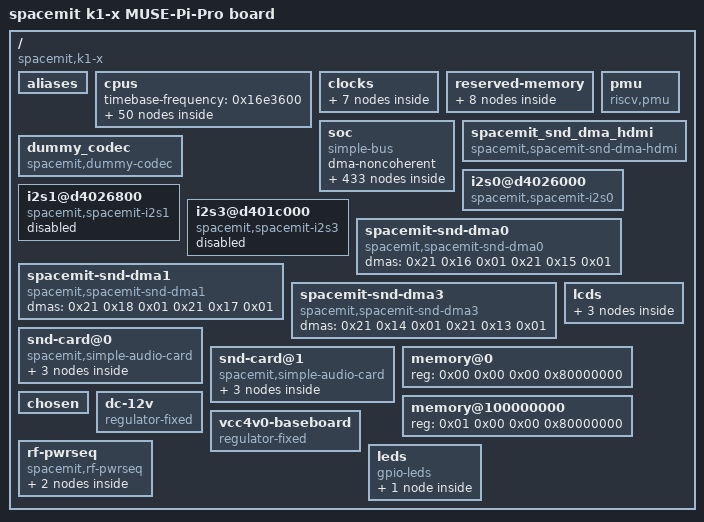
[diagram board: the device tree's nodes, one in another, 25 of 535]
/dts-v1/;

/ {
	compatible = "spacemit,k1-x";
	#address-cells = <0x02>;
	#size-cells = <0x02>;
	model = "spacemit k1-x MUSE-Pi-Pro board";
	modules_usrload = "8852bs";

	aliases {
		serial0 = "/soc/serial@d4017000";
		serial1 = "/soc/uart@f0612000";
		serial2 = "/soc/uart@d4017100";
		serial3 = "/soc/uart@d4017200";
		serial4 = "/soc/uart@d4017300";
		serial5 = "/soc/uart@d4017400";
		serial6 = "/soc/uart@d4017500";
		serial7 = "/soc/uart@d4017600";
		serial8 = "/soc/uart@d4017700";
		serial9 = "/soc/uart@d4017800";
		serial10 = "/soc/r_uart0@c0881000";
		serial11 = "/soc/r_uart1@c088d000";
		mmc0 = "/soc/sdh@d4280000";
		mmc1 = "/soc/sdh@d4280800";
		mmc2 = "/soc/sdh@d4281000";
		ethernet0 = "/soc/ethernet@cac80000";
		ethernet1 = "/soc/ethernet@cac81000";
	};

	cpus {
		#address-cells = <0x01>;
		#size-cells = <0x00>;
		timebase-frequency = <0x16e3600>;

		cpu@0 {
			compatible = "spacemit,x60\0riscv";
			device_type = "cpu";
			model = "Spacemit(R) X60";
			reg = <0x00>;
			status = "okay";
			riscv,isa = "rv64imafdcv";
			riscv,isa-base = "rv64i";
			riscv,isa-extensions = "i\0m\0a\0f\0d\0c\0v\0zicbom\0zicboz\0zicntr\0zicond\0zicsr\0zifencei\0zihintpause\0zihpm\0zfh\0zfhmin\0zba\0zbb\0zbc\0zbs\0zkt\0zvfh\0zvfhmin\0zvkt\0sscofpmf\0sstc\0svinval\0svnapot\0svpbmt";
			riscv,cbom-block-size = <0x40>;
			riscv,cboz-block-size = <0x40>;
			i-cache-block-size = <0x40>;
			i-cache-size = <0x8000>;
			i-cache-sets = <0x80>;
			d-cache-block-size = <0x40>;
			d-cache-size = <0x8000>;
			d-cache-sets = <0x80>;
			next-level-cache = <0x01>;
			mmu-type = "riscv,sv39";
			#cooling-cells = <0x02>;
			clst-supply = <0x02>;
			clocks = <0x03 0x9c 0x03 0xa0>;
			clock-names = "cls0\0cls1";
			operating-points-v2 = <0x04 0x05 0x06>;
			cpu-ai = "true";
			phandle = <0x08>;

			interrupt-controller {
				#interrupt-cells = <0x01>;
				compatible = "riscv,cpu-intc";
				interrupt-controller;
				phandle = <0x10>;
			};
		};

		cpu@1 {
			device_type = "cpu";
			reg = <0x01>;
			status = "okay";
			compatible = "spacemit,x60\0riscv";
			model = "Spacemit(R) X60";
			riscv,isa = "rv64imafdcv";
			riscv,isa-base = "rv64i";
			riscv,isa-extensions = "i\0m\0a\0f\0d\0c\0v\0zicbom\0zicboz\0zicntr\0zicond\0zicsr\0zifencei\0zihintpause\0zihpm\0zfh\0zfhmin\0zba\0zbb\0zbc\0zbs\0zkt\0zvfh\0zvfhmin\0zvkt\0sscofpmf\0sstc\0svinval\0svnapot\0svpbmt";
			riscv,cbom-block-size = <0x40>;
			riscv,cboz-block-size = <0x40>;
			i-cache-block-size = <0x40>;
			i-cache-size = <0x8000>;
			i-cache-sets = <0x80>;
			d-cache-block-size = <0x40>;
			d-cache-size = <0x8000>;
			d-cache-sets = <0x80>;
			next-level-cache = <0x01>;
			mmu-type = "riscv,sv39";
			#cooling-cells = <0x02>;
			clst-supply = <0x02>;
			clocks = <0x03 0x9c 0x03 0xa0>;
			clock-names = "cls0\0cls1";
			operating-points-v2 = <0x04 0x05 0x06>;
			cpu-ai = "true";
			phandle = <0x09>;

			interrupt-controller {
				#interrupt-cells = <0x01>;
				compatible = "riscv,cpu-intc";
				interrupt-controller;
				phandle = <0x11>;
			};
		};

		cpu@2 {
			device_type = "cpu";
			reg = <0x02>;
			status = "okay";
			compatible = "spacemit,x60\0riscv";
			model = "Spacemit(R) X60";
			riscv,isa = "rv64imafdcv";
			riscv,isa-base = "rv64i";
			riscv,isa-extensions = "i\0m\0a\0f\0d\0c\0v\0zicbom\0zicboz\0zicntr\0zicond\0zicsr\0zifencei\0zihintpause\0zihpm\0zfh\0zfhmin\0zba\0zbb\0zbc\0zbs\0zkt\0zvfh\0zvfhmin\0zvkt\0sscofpmf\0sstc\0svinval\0svnapot\0svpbmt";
			riscv,cbom-block-size = <0x40>;
			riscv,cboz-block-size = <0x40>;
			i-cache-block-size = <0x40>;
			i-cache-size = <0x8000>;
			i-cache-sets = <0x80>;
			d-cache-block-size = <0x40>;
			d-cache-size = <0x8000>;
			d-cache-sets = <0x80>;
			next-level-cache = <0x01>;
			mmu-type = "riscv,sv39";
			#cooling-cells = <0x02>;
			clst-supply = <0x02>;
			clocks = <0x03 0x9c 0x03 0xa0>;
			clock-names = "cls0\0cls1";
			operating-points-v2 = <0x04 0x05 0x06>;
			cpu-ai = "true";
			phandle = <0x0a>;

			interrupt-controller {
				#interrupt-cells = <0x01>;
				compatible = "riscv,cpu-intc";
				interrupt-controller;
				phandle = <0x12>;
			};
		};

		cpu@3 {
			device_type = "cpu";
			reg = <0x03>;
			status = "okay";
			compatible = "spacemit,x60\0riscv";
			model = "Spacemit(R) X60";
			riscv,isa = "rv64imafdcv";
			riscv,isa-base = "rv64i";
			riscv,isa-extensions = "i\0m\0a\0f\0d\0c\0v\0zicbom\0zicboz\0zicntr\0zicond\0zicsr\0zifencei\0zihintpause\0zihpm\0zfh\0zfhmin\0zba\0zbb\0zbc\0zbs\0zkt\0zvfh\0zvfhmin\0zvkt\0sscofpmf\0sstc\0svinval\0svnapot\0svpbmt";
			riscv,cbom-block-size = <0x40>;
			riscv,cboz-block-size = <0x40>;
			i-cache-block-size = <0x40>;
			i-cache-size = <0x8000>;
			i-cache-sets = <0x80>;
			d-cache-block-size = <0x40>;
			d-cache-size = <0x8000>;
			d-cache-sets = <0x80>;
			next-level-cache = <0x01>;
			mmu-type = "riscv,sv39";
			#cooling-cells = <0x02>;
			clst-supply = <0x02>;
			clocks = <0x03 0x9c 0x03 0xa0>;
			clock-names = "cls0\0cls1";
			operating-points-v2 = <0x04 0x05 0x06>;
			cpu-ai = "true";
			phandle = <0x0b>;

			interrupt-controller {
				#interrupt-cells = <0x01>;
				compatible = "riscv,cpu-intc";
				interrupt-controller;
				phandle = <0x13>;
			};
		};

		cpu@4 {
			device_type = "cpu";
			reg = <0x04>;
			status = "okay";
			compatible = "spacemit,x60\0riscv";
			model = "Spacemit(R) X60";
			riscv,isa = "rv64imafdcv";
			riscv,isa-base = "rv64i";
			riscv,isa-extensions = "i\0m\0a\0f\0d\0c\0v\0zicbom\0zicboz\0zicntr\0zicond\0zicsr\0zifencei\0zihintpause\0zihpm\0zfh\0zfhmin\0zba\0zbb\0zbc\0zbs\0zkt\0zvfh\0zvfhmin\0zvkt\0sscofpmf\0sstc\0svinval\0svnapot\0svpbmt";
			riscv,cbom-block-size = <0x40>;
			riscv,cboz-block-size = <0x40>;
			i-cache-block-size = <0x40>;
			i-cache-size = <0x8000>;
			i-cache-sets = <0x80>;
			d-cache-block-size = <0x40>;
			d-cache-size = <0x8000>;
			d-cache-sets = <0x80>;
			next-level-cache = <0x07>;
			mmu-type = "riscv,sv39";
			#cooling-cells = <0x02>;
			clst-supply = <0x02>;
			clocks = <0x03 0x9c 0x03 0xa0>;
			clock-names = "cls0\0cls1";
			operating-points-v2 = <0x04 0x05 0x06>;
			phandle = <0x0c>;

			interrupt-controller {
				#interrupt-cells = <0x01>;
				compatible = "riscv,cpu-intc";
				interrupt-controller;
				phandle = <0x14>;
			};
		};

		cpu@5 {
			device_type = "cpu";
			reg = <0x05>;
			status = "okay";
			compatible = "spacemit,x60\0riscv";
			model = "Spacemit(R) X60";
			riscv,isa = "rv64imafdcv";
			riscv,isa-base = "rv64i";
			riscv,isa-extensions = "i\0m\0a\0f\0d\0c\0v\0zicbom\0zicboz\0zicntr\0zicond\0zicsr\0zifencei\0zihintpause\0zihpm\0zfh\0zfhmin\0zba\0zbb\0zbc\0zbs\0zkt\0zvfh\0zvfhmin\0zvkt\0sscofpmf\0sstc\0svinval\0svnapot\0svpbmt";
			riscv,cbom-block-size = <0x40>;
			riscv,cboz-block-size = <0x40>;
			i-cache-block-size = <0x40>;
			i-cache-size = <0x8000>;
			i-cache-sets = <0x80>;
			d-cache-block-size = <0x40>;
			d-cache-size = <0x8000>;
			d-cache-sets = <0x80>;
			next-level-cache = <0x07>;
			mmu-type = "riscv,sv39";
			#cooling-cells = <0x02>;
			clst-supply = <0x02>;
			clocks = <0x03 0x9c 0x03 0xa0>;
			clock-names = "cls0\0cls1";
			operating-points-v2 = <0x04 0x05 0x06>;
			phandle = <0x0d>;

			interrupt-controller {
				#interrupt-cells = <0x01>;
				compatible = "riscv,cpu-intc";
				interrupt-controller;
				phandle = <0x15>;
			};
		};

		cpu@6 {
			device_type = "cpu";
			reg = <0x06>;
			status = "okay";
			compatible = "spacemit,x60\0riscv";
			model = "Spacemit(R) X60";
			riscv,isa = "rv64imafdcv";
			riscv,isa-base = "rv64i";
			riscv,isa-extensions = "i\0m\0a\0f\0d\0c\0v\0zicbom\0zicboz\0zicntr\0zicond\0zicsr\0zifencei\0zihintpause\0zihpm\0zfh\0zfhmin\0zba\0zbb\0zbc\0zbs\0zkt\0zvfh\0zvfhmin\0zvkt\0sscofpmf\0sstc\0svinval\0svnapot\0svpbmt";
			riscv,cbom-block-size = <0x40>;
			riscv,cboz-block-size = <0x40>;
			i-cache-block-size = <0x40>;
			i-cache-size = <0x8000>;
			i-cache-sets = <0x80>;
			d-cache-block-size = <0x40>;
			d-cache-size = <0x8000>;
			d-cache-sets = <0x80>;
			next-level-cache = <0x07>;
			mmu-type = "riscv,sv39";
			#cooling-cells = <0x02>;
			clst-supply = <0x02>;
			clocks = <0x03 0x9c 0x03 0xa0>;
			clock-names = "cls0\0cls1";
			operating-points-v2 = <0x04 0x05 0x06>;
			phandle = <0x0e>;

			interrupt-controller {
				#interrupt-cells = <0x01>;
				compatible = "riscv,cpu-intc";
				interrupt-controller;
				phandle = <0x16>;
			};
		};

		cpu@7 {
			device_type = "cpu";
			reg = <0x07>;
			status = "okay";
			compatible = "spacemit,x60\0riscv";
			model = "Spacemit(R) X60";
			riscv,isa = "rv64imafdcv";
			riscv,isa-base = "rv64i";
			riscv,isa-extensions = "i\0m\0a\0f\0d\0c\0v\0zicbom\0zicboz\0zicntr\0zicond\0zicsr\0zifencei\0zihintpause\0zihpm\0zfh\0zfhmin\0zba\0zbb\0zbc\0zbs\0zkt\0zvfh\0zvfhmin\0zvkt\0sscofpmf\0sstc\0svinval\0svnapot\0svpbmt";
			riscv,cbom-block-size = <0x40>;
			riscv,cboz-block-size = <0x40>;
			i-cache-block-size = <0x40>;
			i-cache-size = <0x8000>;
			i-cache-sets = <0x80>;
			d-cache-block-size = <0x40>;
			d-cache-size = <0x8000>;
			d-cache-sets = <0x80>;
			next-level-cache = <0x07>;
			mmu-type = "riscv,sv39";
			#cooling-cells = <0x02>;
			clst-supply = <0x02>;
			clocks = <0x03 0x9c 0x03 0xa0>;
			clock-names = "cls0\0cls1";
			operating-points-v2 = <0x04 0x05 0x06>;
			phandle = <0x0f>;

			interrupt-controller {
				#interrupt-cells = <0x01>;
				compatible = "riscv,cpu-intc";
				interrupt-controller;
				phandle = <0x17>;
			};
		};

		l2-cache0 {
			compatible = "cache";
			cache-block-size = <0x40>;
			cache-level = <0x02>;
			cache-size = <0x80000>;
			cache-sets = <0x200>;
			cache-unified;
			phandle = <0x01>;
		};

		l2-cache1 {
			compatible = "cache";
			cache-block-size = <0x40>;
			cache-level = <0x02>;
			cache-size = <0x80000>;
			cache-sets = <0x200>;
			cache-unified;
			phandle = <0x07>;
		};

		opp_table0 {
			compatible = "operating-points-v2";
			opp-shared;
			clocks = <0x03 0x9d 0x03 0xa1 0x03 0x9e 0x03 0x99 0x03 0x01 0x03 0x9b 0x03 0x9f>;
			clock-names = "ace0\0ace1\0tcm\0cci\0pll3\0c0hi\0c1hi";
			cci-hz = <0x00 0x2498e580>;
			phandle = <0x04>;

			opp1800000000 {
				opp-hz = <0x00 0x6b49d200 0x00 0x6b49d200>;
				tcm-hz = <0x00 0x35a4e900>;
				ace-hz = <0x00 0x35a4e900>;
				opp-microvolt = <0x11b340>;
				clock-latency-ns = <0x30d40>;
				turbo-mode;
			};

			opp1600000000 {
				opp-hz = <0x00 0x5f5e1000 0x00 0x5f5e1000>;
				tcm-hz = <0x00 0x2faf0800>;
				ace-hz = <0x00 0x2faf0800>;
				opp-microvolt = <0x100590>;
				clock-latency-ns = <0x30d40>;
			};

			opp1228800000 {
				opp-hz = <0x00 0x493e0000 0x00 0x493e0000>;
				tcm-hz = <0x00 0x249f0000>;
				ace-hz = <0x00 0x249f0000>;
				opp-microvolt = <0xe7ef0>;
				clock-latency-ns = <0x30d40>;
			};

			opp1000000000 {
				opp-hz = <0x00 0x3b9aca00 0x00 0x3b9aca00>;
				tcm-hz = <0x00 0x1dcd6500>;
				ace-hz = <0x00 0x1dcd6500>;
				opp-microvolt = <0xe7ef0>;
				clock-latency-ns = <0x30d40>;
			};

			opp819000000 {
				opp-hz = <0x00 0x30d0f2c0 0x00 0x30d0f2c0>;
				opp-microvolt = <0xe7ef0>;
				tcm-hz = <0x00 0x18687960>;
				ace-hz = <0x00 0x18687960>;
				clock-latency-ns = <0x30d40>;
			};

			opp614400000 {
				opp-hz = <0x00 0x249f0000 0x00 0x249f0000>;
				tcm-hz = <0x00 0x124f8000>;
				ace-hz = <0x00 0x124f8000>;
				opp-microvolt = <0xe7ef0>;
				clock-latency-ns = <0x30d40>;
			};
		};

		opp_table1 {
			compatible = "operating-points-v2";
			opp-shared;
			clocks = <0x03 0x9d 0x03 0xa1 0x03 0x9e 0x03 0x99 0x03 0x01 0x03 0x9b 0x03 0x9f>;
			clock-names = "ace0\0ace1\0tcm\0cci\0pll3\0c0hi\0c1hi";
			cci-hz = <0x00 0x2498e580>;
			phandle = <0x05>;

			opp1800000000 {
				opp-hz = <0x00 0x6b49d200 0x00 0x6b49d200>;
				tcm-hz = <0x00 0x35a4e900>;
				ace-hz = <0x00 0x35a4e900>;
				opp-microvolt = <0x10c8e0>;
				clock-latency-ns = <0x30d40>;
				turbo-mode;
			};

			opp1600000000 {
				opp-hz = <0x00 0x5f5e1000 0x00 0x5f5e1000>;
				tcm-hz = <0x00 0x2faf0800>;
				ace-hz = <0x00 0x2faf0800>;
				opp-microvolt = <0x100590>;
				clock-latency-ns = <0x30d40>;
			};

			opp1228800000 {
				opp-hz = <0x00 0x493e0000 0x00 0x493e0000>;
				tcm-hz = <0x00 0x249f0000>;
				ace-hz = <0x00 0x249f0000>;
				opp-microvolt = <0xe7ef0>;
				clock-latency-ns = <0x30d40>;
			};

			opp1000000000 {
				opp-hz = <0x00 0x3b9aca00 0x00 0x3b9aca00>;
				tcm-hz = <0x00 0x1dcd6500>;
				ace-hz = <0x00 0x1dcd6500>;
				opp-microvolt = <0xe7ef0>;
				clock-latency-ns = <0x30d40>;
			};

			opp819000000 {
				opp-hz = <0x00 0x30d0f2c0 0x00 0x30d0f2c0>;
				opp-microvolt = <0xe7ef0>;
				tcm-hz = <0x00 0x18687960>;
				ace-hz = <0x00 0x18687960>;
				clock-latency-ns = <0x30d40>;
			};

			opp614400000 {
				opp-hz = <0x00 0x249f0000 0x00 0x249f0000>;
				tcm-hz = <0x00 0x124f8000>;
				ace-hz = <0x00 0x124f8000>;
				opp-microvolt = <0xe7ef0>;
				clock-latency-ns = <0x30d40>;
			};
		};

		opp_table2 {
			compatible = "operating-points-v2";
			opp-shared;
			clocks = <0x03 0x9d 0x03 0xa1 0x03 0x9e 0x03 0x99 0x03 0x01 0x03 0x9b 0x03 0x9f>;
			clock-names = "ace0\0ace1\0tcm\0cci\0pll3\0c0hi\0c1hi";
			cci-hz = <0x00 0x2498e580>;
			phandle = <0x06>;

			opp1800000000 {
				opp-hz = <0x00 0x6b49d200 0x00 0x6b49d200>;
				tcm-hz = <0x00 0x35a4e900>;
				ace-hz = <0x00 0x35a4e900>;
				opp-microvolt = <0x100590>;
				clock-latency-ns = <0x30d40>;
				turbo-mode;
			};

			opp1600000000 {
				opp-hz = <0x00 0x5f5e1000 0x00 0x5f5e1000>;
				tcm-hz = <0x00 0x2faf0800>;
				ace-hz = <0x00 0x2faf0800>;
				opp-microvolt = <0x100590>;
				clock-latency-ns = <0x30d40>;
			};

			opp1228800000 {
				opp-hz = <0x00 0x493e0000 0x00 0x493e0000>;
				tcm-hz = <0x00 0x249f0000>;
				ace-hz = <0x00 0x249f0000>;
				opp-microvolt = <0xe7ef0>;
				clock-latency-ns = <0x30d40>;
			};

			opp1000000000 {
				opp-hz = <0x00 0x3b9aca00 0x00 0x3b9aca00>;
				tcm-hz = <0x00 0x1dcd6500>;
				ace-hz = <0x00 0x1dcd6500>;
				opp-microvolt = <0xe7ef0>;
				clock-latency-ns = <0x30d40>;
			};

			opp819000000 {
				opp-hz = <0x00 0x30d0f2c0 0x00 0x30d0f2c0>;
				opp-microvolt = <0xe7ef0>;
				tcm-hz = <0x00 0x18687960>;
				ace-hz = <0x00 0x18687960>;
				clock-latency-ns = <0x30d40>;
			};

			opp614400000 {
				opp-hz = <0x00 0x249f0000 0x00 0x249f0000>;
				tcm-hz = <0x00 0x124f8000>;
				ace-hz = <0x00 0x124f8000>;
				opp-microvolt = <0xe7ef0>;
				clock-latency-ns = <0x30d40>;
			};
		};

		cpu-map {

			cluster0 {

				core0 {
					cpu = <0x08>;
				};

				core1 {
					cpu = <0x09>;
				};

				core2 {
					cpu = <0x0a>;
				};

				core3 {
					cpu = <0x0b>;
				};
			};

			cluster1 {

				core0 {
					cpu = <0x0c>;
				};

				core1 {
					cpu = <0x0d>;
				};

				core2 {
					cpu = <0x0e>;
				};

				core3 {
					cpu = <0x0f>;
				};
			};
		};
	};

	clocks {
		#address-cells = <0x02>;
		#size-cells = <0x02>;
		ranges;

		clock-vctcxo_24 {
			#clock-cells = <0x00>;
			compatible = "fixed-clock";
			clock-frequency = <0x16e3600>;
			clock-output-names = "vctcxo_24";
			phandle = <0x18>;
		};

		clock-vctcxo_3 {
			#clock-cells = <0x00>;
			compatible = "fixed-clock";
			clock-frequency = <0x2dc6c0>;
			clock-output-names = "vctcxo_3";
			phandle = <0x19>;
		};

		clock-vctcxo_1 {
			#clock-cells = <0x00>;
			compatible = "fixed-clock";
			clock-frequency = <0xf4240>;
			clock-output-names = "vctcxo_1";
			phandle = <0x1a>;
		};

		clock-pll1_2457p6_vco {
			#clock-cells = <0x00>;
			compatible = "fixed-clock";
			clock-frequency = <0x927c0000>;
			clock-output-names = "pll1_2457p6_vco";
			phandle = <0x1b>;
		};

		clock-clk32k {
			#clock-cells = <0x00>;
			compatible = "fixed-clock";
			clock-frequency = <0x7d00>;
			clock-output-names = "clk_32k";
			phandle = <0x1c>;
		};

		clock-pll_clk_cluster0 {
			#clock-cells = <0x00>;
			compatible = "fixed-clock";
			clock-frequency = <0x989680>;
			clock-output-names = "pll_clk_cluster0";
		};

		clock-pll_clk_cluster1 {
			#clock-cells = <0x00>;
			compatible = "fixed-clock";
			clock-frequency = <0x989680>;
			clock-output-names = "pll_clk_cluster1";
		};
	};

	reserved-memory {
		#address-cells = <0x02>;
		#size-cells = <0x02>;
		ranges;

		rcpu_mem_heap@100000 {
			reg = <0x00 0x100000 0x00 0x200000>;
			da_base = <0x30000000>;
			no-map;
			phandle = <0x28>;
		};

		vdev0vring0@300000 {
			reg = <0x00 0x300000 0x00 0x3000>;
			da_base = "0 \0";
			no-map;
			phandle = <0x29>;
		};

		vdev0vring1@303000 {
			reg = <0x00 0x303000 0x00 0x3000>;
			da_base = "0 0";
			no-map;
			phandle = <0x2a>;
		};

		vdev0buffer@306000 {
			compatible = "shared-dma-pool";
			reg = <0x00 0x306000 0x00 0xf6000>;
			da_base = "0 `";
			no-map;
			phandle = <0x2b>;
		};

		rsc_table@3fc000 {
			reg = <0x00 0x3fc000 0x00 0x4000>;
			da_base = <0x302fc000>;
			no-map;
			phandle = <0x2c>;
		};

		rcpu_mem_0@400000 {
			reg = <0x00 0x400000 0x00 0x200000>;
			da_base = "00\0";
			no-map;
			phandle = <0x27>;
		};

		linux,cma {
			compatible = "shared-dma-pool";
			alloc-ranges = <0x00 0x40000000 0x00 0x30000000>;
			size = <0x00 0x18000000>;
			alignment = <0x00 0x100000>;
			linux,cma-default;
			reusable;
		};

		dpu_reserved@2ff40000 {
			compatible = "shared-dma-pool";
			reg = <0x00 0x2ff40000 0x00 0xc0000>;
			no-map;
			phandle = <0x6a>;
		};
	};

	soc {
		compatible = "simple-bus";
		#address-cells = <0x02>;
		#size-cells = <0x02>;
		dma-noncoherent;
		ranges;

		dram_range@0 {
			compatible = "spacemit-dram-bus";
			#address-cells = <0x02>;
			#size-cells = <0x02>;
			dma-ranges = <0x00 0x00 0x00 0x00 0x00 0x80000000>;
			#interconnect-cells = <0x00>;
			status = "okay";
			phandle = <0x47>;
		};

		dram_range@1 {
			compatible = "spacemit-dram-bus";
			#address-cells = <0x02>;
			#size-cells = <0x02>;
			dma-ranges = <0x00 0x00 0x00 0x00 0x00 0x80000000 0x00 0x80000000 0x01 0x00 0x03 0x80000000>;
			#interconnect-cells = <0x00>;
			status = "okay";
			phandle = <0x61>;
		};

		dram_range@2 {
			compatible = "spacemit-dram-bus";
			#address-cells = <0x02>;
			#size-cells = <0x02>;
			dma-ranges = <0x00 0x00 0x00 0x00 0x00 0x80000000 0x00 0x90000000 0x01 0x10000000 0x03 0x70000000>;
			#interconnect-cells = <0x00>;
			status = "okay";
			phandle = <0x53>;
		};

		dram_range@3 {
			compatible = "spacemit-dram-bus";
			#address-cells = <0x02>;
			#size-cells = <0x02>;
			dma-ranges = <0x00 0x00 0x00 0x00 0x00 0x80000000 0x00 0x80000000 0x01 0x00 0x01 0x80000000>;
			#interconnect-cells = <0x00>;
			status = "okay";
			phandle = <0x62>;
		};

		dram_range@4 {
			compatible = "spacemit-dram-bus";
			#address-cells = <0x02>;
			#size-cells = <0x02>;
			dma-ranges = <0x00 0x00 0x00 0x00 0x00 0x80000000 0x01 0x00 0x01 0x80000000 0x03 0x00>;
			#interconnect-cells = <0x00>;
			status = "okay";
			phandle = <0x22>;
		};

		dram_range@5 {
			compatible = "spacemit-dram-bus";
			#address-cells = <0x02>;
			#size-cells = <0x02>;
			dma-ranges = <0x00 0x00 0x00 0x00 0x00 0x80000000 0x00 0x80000000 0x01 0x00 0x00 0x80000000>;
			#interconnect-cells = <0x00>;
			status = "okay";
			phandle = <0x42>;
		};

		dram_range@6 {
			compatible = "spacemit-dram-bus";
			#address-cells = <0x02>;
			#size-cells = <0x02>;
			dma-ranges = <0x00 0x00 0x00 0x00 0x00 0x80000000 0x00 0x80000000 0x01 0x00 0x00 0x10000000 0x00 0xa0000000 0x01 0x20000000 0x03 0x60000000>;
			#interconnect-cells = <0x00>;
			status = "okay";
			phandle = <0x55>;
		};

		dram_range@7 {
			compatible = "spacemit-dram-bus";
			#address-cells = <0x02>;
			#size-cells = <0x02>;
			dma-ranges = <0x00 0x00 0x00 0x00 0x00 0x80000000 0x00 0x80000000 0x01 0x00 0x00 0x20000000 0x00 0xb8000000 0x01 0x38000000 0x03 0x48000000>;
			#interconnect-cells = <0x00>;
			status = "okay";
			phandle = <0x58>;
		};

		dram_range@8 {
			compatible = "spacemit-dram-bus";
			#address-cells = <0x02>;
			#size-cells = <0x02>;
			dma-ranges = <0x00 0x30200000 0x00 0x300000 0x00 0xfc000>;
			#interconnect-cells = <0x00>;
			status = "okay";
			phandle = <0x26>;
		};

		clint@e4000000 {
			compatible = "riscv,clint0";
			interrupts-extended = <0x10 0x03 0x10 0x07 0x11 0x03 0x11 0x07 0x12 0x03 0x12 0x07 0x13 0x03 0x13 0x07 0x14 0x03 0x14 0x07 0x15 0x03 0x15 0x07 0x16 0x03 0x16 0x07 0x17 0x03 0x17 0x07>;
			reg = <0x00 0xe4000000 0x00 0x10000>;
		};

		clock-controller@d4050000 {
			compatible = "spacemit,k1x-clock";
			reg = <0x00 0xd4050000 0x00 0x209c 0x00 0xd4282800 0x00 0x400 0x00 0xd4015000 0x00 0x1000 0x00 0xd4090000 0x00 0x1000 0x00 0xd4282c00 0x00 0x400 0x00 0xd8440000 0x00 0x98 0x00 0xc0000000 0x00 0x4280 0x00 0xf0610000 0x00 0x20 0x00 0xc0880000 0x00 0x2050 0x00 0xc0888000 0x00 0x30 0x00 0xc088c000 0x00 0x40>;
			reg-names = "mpmu\0apmu\0apbc\0apbs\0ciu\0dciu\0ddrc\0apbc2\0rcpu\0rcpu2\0audpmu";
			clocks = <0x18 0x19 0x1a 0x1b 0x1c>;
			clock-names = "vctcxo_24\0vctcxo_3\0vctcxo_1\0pll1_2457p6_vco\0clk_32k";
			#clock-cells = <0x01>;
			status = "okay";
			phandle = <0x03>;
		};

		reset-controller@d4050000 {
			compatible = "spacemit,k1x-reset";
			reg = <0x00 0xd4050000 0x00 0x209c 0x00 0xd4282800 0x00 0x400 0x00 0xd4015000 0x00 0x1000 0x00 0xd4090000 0x00 0x1000 0x00 0xd4282c00 0x00 0x400 0x00 0xd8440000 0x00 0x98 0x00 0xc0000000 0x00 0x4280 0x00 0xf0610000 0x00 0x20 0x00 0xc0880000 0x00 0x2050 0x00 0xc0888000 0x00 0x30>;
			reg-names = "mpmu\0apmu\0apbc\0apbs\0ciu\0dciu\0ddrc\0apbc2\0rcpu\0rcpu2";
			#reset-cells = <0x01>;
			status = "okay";
			phandle = <0x1d>;
		};

		interrupt-controller@e0000000 {
			#interrupt-cells = <0x01>;
			compatible = "riscv,plic0";
			interrupt-controller;
			interrupts-extended = <0x10 0x0b 0x10 0x09 0x11 0x0b 0x11 0x09 0x12 0x0b 0x12 0x09 0x13 0x0b 0x13 0x09 0x14 0x0b 0x14 0x09 0x15 0x0b 0x15 0x09 0x16 0x0b 0x16 0x09 0x17 0x0b 0x17 0x09>;
			reg = <0x00 0xe0000000 0x00 0x4000000>;
			reg-names = "control";
			riscv,max-priority = <0x07>;
			riscv,ndev = <0x9f>;
			phandle = <0x1e>;
		};

		pinctrl@d401e000 {
			compatible = "pinconf-single-aib";
			reg = <0x00 0xd401e000 0x00 0x27c 0x00 0xd4019800 0x00 0x10 0x00 0xd4019000 0x00 0x800 0x00 0xd4282904 0x00 0x04>;
			#address-cells = <0x01>;
			#size-cells = <0x01>;
			#pinctrl-cells = <0x02>;
			#gpio-range-cells = <0x03>;
			pinctrl-single,register-width = <0x20>;
			pinctrl-single,function-mask = <0xff77>;
			clocks = <0x03 0x64>;
			clock-names = "clk_aib";
			resets = <0x1d 0x1d>;
			reset-names = "aib_rst";
			interrupt-parent = <0x1e>;
			interrupts = <0x3c>;
			interrupt-controller;
			#interrupt-cells = <0x01>;
			pinctrl-single,gpio-range = <0x1f 0x32 0x02 0xc440 0x1f 0x3b 0x01 0xd040 0x1f 0x40 0x01 0xd040 0x1f 0x41 0x01 0xd041 0x1f 0x42 0x01 0xd040 0x1f 0x44 0x01 0xc440 0x1f 0x47 0x02 0xd041 0x1f 0x49 0x01 0xb041 0x1f 0x4a 0x01 0xd041 0x1f 0x4b 0x01 0xd040 0x1f 0x50 0x01 0xd040 0x1f 0x51 0x01 0xc440 0x1f 0x52 0x03 0xd040 0x1f 0x7f 0x01 0xb040 0x1f 0x80 0x02 0xd040 0x1f 0x78 0x01 0xb041 0x1f 0x79 0x01 0xa041 0x1f 0x74 0x01 0xb040 0x1f 0x83 0x01 0xb040 0x1f 0x85 0x01 0xb040 0x1f 0x86 0x01 0xb040 0x1f 0x87 0x01 0xb040 0x1f 0x88 0x01 0xd040 0x1f 0x8a 0x01 0xd040 0x1f 0x8f 0x01 0xa040 0x1f 0x90 0x01 0xd040 0x1f 0x91 0x03 0xb040>;
			phandle = <0x3f>;

			gpio-range {
				#pinctrl-single,gpio-range-cells = <0x03>;
				phandle = <0x1f>;
			};

			uart0_0_grp {
				pinctrl-single,pins = <0x1b8 0x03 0xc440 0x1bc 0x03 0xc440>;
			};

			uart0_1_grp {
				pinctrl-single,pins = <0x1c8 0x01 0xc440 0x144 0x03 0xc440>;
			};

			uart0_2_grp {
				pinctrl-single,pins = <0x114 0x02 0xd040 0x118 0x02 0xd040>;
				phandle = <0x23>;
			};

			uart2_grp {
				pinctrl-single,pins = <0x58 0x01 0xd040 0x5c 0x01 0xd040 0x60 0x01 0xd040 0x64 0x01 0xd040>;
				phandle = <0x24>;
			};

			uart3_0_grp {
				pinctrl-single,pins = <0x148 0x02 0xd040 0x14c 0x02 0xd040 0x150 0x02 0xd040 0x154 0x02 0xd040>;
			};

			uart3_1_grp {
				pinctrl-single,pins = <0x4c 0x02 0xd040 0x50 0x02 0xd040 0x54 0x02 0xd040 0x58 0x02 0xd040>;
			};

			uart3_2_grp {
				pinctrl-single,pins = <0xd8 0x04 0xd040 0xdc 0x04 0xd040 0xe0 0x04 0xd040 0xe4 0x04 0xd040>;
			};

			uart4_0_grp {
				pinctrl-single,pins = <0x16c 0x04 0xc440 0x168 0x04 0xc440>;
			};

			uart4_1_grp {
				pinctrl-single,pins = <0x148 0x03 0xd040 0x14c 0x03 0xd040 0x150 0x03 0xd040 0x154 0x03 0xd040>;
			};

			uart4_2_grp {
				pinctrl-single,pins = <0x60 0x02 0xd040 0x64 0x02 0xd040>;
			};

			uart4_3_grp {
				pinctrl-single,pins = <0x88 0x02 0xd040 0x8c 0x02 0xd040 0x90 0x02 0xd040 0x94 0x02 0xd040>;
				phandle = <0x92>;
			};

			uart4_4_grp {
				pinctrl-single,pins = <0x20c 0x04 0xd040 0x210 0x04 0xd040 0x214 0x04 0xd040 0x218 0x04 0xd040>;
			};

			uart5_0_grp {
				pinctrl-single,pins = <0x17c 0x03 0xc440 0x178 0x03 0xc440>;
			};

			uart5_1_grp {
				pinctrl-single,pins = <0x68 0x02 0xd040 0x6c 0x02 0xd040 0x70 0x02 0xd040 0x74 0x02 0xd040>;
			};

			uart5_2_grp {
				pinctrl-single,pins = <0xac 0x02 0xd040 0xb0 0x02 0xd040 0xb4 0x02 0xd040 0xb8 0x02 0xd040>;
			};

			uart5_3_grp {
				pinctrl-single,pins = <0x11c 0x04 0xd040 0x120 0x04 0xd040 0x124 0x04 0xd040 0x128 0x04 0xd040>;
				phandle = <0x91>;
			};

			uart6_0_grp {
				pinctrl-single,pins = <0x158 0x02 0xd040 0x1ec 0x02 0xd040 0x1f0 0x02 0xd040 0x1fc 0x02 0xd040>;
			};

			uart6_1_grp {
				pinctrl-single,pins = <0x04 0x02 0xd040 0x08 0x02 0xd040 0x0c 0x02 0xd040 0x10 0x02 0xd040>;
			};

			uart6_2_grp {
				pinctrl-single,pins = <0xe4 0x02 0xd040 0xe8 0x02 0xd040>;
			};

			uart7_0_grp {
				pinctrl-single,pins = <0x1f4 0x02 0xd040 0x1f8 0x02 0xd040>;
			};

			uart7_1_grp {
				pinctrl-single,pins = <0x14 0x02 0xd040 0x18 0x02 0xd040 0x1c 0x02 0xd040 0x20 0x02 0xd040>;
			};

			uart8_0_grp {
				pinctrl-single,pins = <0x14c 0x04 0xd040 0x150 0x04 0xd040>;
			};

			uart8_1_grp {
				pinctrl-single,pins = <0x24 0x02 0xd040 0x28 0x02 0xd040 0x2c 0x02 0xd040 0x30 0x02 0xd040>;
			};

			uart8_2_grp {
				pinctrl-single,pins = <0x130 0x04 0xc440 0x134 0x04 0xc440 0x138 0x04 0xc440 0x13c 0x04 0xc440>;
			};

			uart9_0_grp {
				pinctrl-single,pins = <0x34 0x02 0xd040 0x38 0x02 0xd040>;
			};

			uart9_1_grp {
				pinctrl-single,pins = <0x1d0 0x03 0xd040 0x21c 0x03 0xd040 0x220 0x03 0xd040 0x224 0x03 0xd040>;
			};

			uart9_2_grp {
				pinctrl-single,pins = <0x124 0x02 0xd040 0x128 0x02 0xd040>;
			};

			i2c0_grp {
				pinctrl-single,pins = <0xdc 0x01 0xd040 0xe0 0x01 0xd040>;
				phandle = <0x2f>;
			};

			r_uart1_grp {
				pinctrl-single,pins = <0xc8 0x02 0xc440 0xcc 0x02 0xc440 0xd0 0x02 0xc440 0xd4 0x02 0xc440>;
			};

			i2c1_grp {
				pinctrl-single,pins = <0xe4 0x01 0xd040 0xe8 0x01 0xd040>;
				phandle = <0x30>;
			};

			i2c2_0_grp {
				pinctrl-single,pins = <0x154 0x04 0xd040 0x158 0x04 0xd040>;
				phandle = <0x31>;
			};

			i2c2_1_grp {
				pinctrl-single,pins = <0x11c 0x02 0xd040 0x120 0x02 0xd040>;
			};

			i2c2_2_grp {
				pinctrl-single,pins = <0x114 0x03 0xd040 0x118 0x03 0xd040>;
			};

			i2c3_0_grp {
				pinctrl-single,pins = <0x9c 0x02 0xd040 0xa0 0x02 0xd040>;
				phandle = <0x33>;
			};

			i2c3_1_grp {
				pinctrl-single,pins = <0xc0 0x04 0xd040 0xc4 0x04 0xd040>;
			};

			i2c3_2_grp {
				pinctrl-single,pins = <0x138 0x03 0xd040 0x13c 0x03 0xd040>;
			};

			i2c4_0_grp {
				pinctrl-single,pins = <0xa4 0x02 0xd040 0xa8 0x02 0xd040>;
				phandle = <0x34>;
			};

			i2c4_1_grp {
				pinctrl-single,pins = <0x130 0x05 0xd040 0x134 0x05 0xd040>;
			};

			i2c4_2_grp {
				pinctrl-single,pins = <0xd0 0x04 0xd040 0xd4 0x04 0xd040>;
			};

			i2c5_0_grp {
				pinctrl-single,pins = <0x148 0x05 0xd040 0x14c 0x05 0xd040>;
				phandle = <0x35>;
			};

			i2c5_1_grp {
				pinctrl-single,pins = <0xdc 0x05 0xd040 0xe0 0x05 0xd040>;
			};

			i2c6_0_grp {
				pinctrl-single,pins = <0x150 0x05 0xd040 0x1fc 0x05 0xd040>;
			};

			i2c6_1_grp {
				pinctrl-single,pins = <0x228 0x02 0xd040 0x22c 0x02 0xd040>;
			};

			i2c6_2_grp {
				pinctrl-single,pins = <0xe4 0x05 0xd040 0xe8 0x05 0xd040>;
				phandle = <0x37>;
			};

			i2c7_grp {
				pinctrl-single,pins = <0x228 0x01 0xd040 0x22c 0x01 0xd040>;
				phandle = <0x38>;
			};

			i2c8_grp {
				pinctrl-single,pins = <0x1d4 0x00 0xd040 0x1d8 0x00 0xd040>;
				phandle = <0x39>;
			};

			one_wire_0_grp {
				pinctrl-single,pins = <0x1d0 0x05 0xd040>;
			};

			one_wire_1_grp {
				pinctrl-single,pins = <0xc0 0x05 0xc440>;
			};

			ir_rx_0_grp {
				pinctrl-single,pins = <0x1e4 0x02 0xd040>;
			};

			ir_rx_1_grp {
				pinctrl-single,pins = <0x140 0x01 0xc440>;
			};

			ir_rx_2_grp {
				pinctrl-single,pins = <0xec 0x04 0xd040>;
			};

			r_ir_rx_0_grp {
				pinctrl-single,pins = <0xc4 0x03 0xc440>;
			};

			r_ir_rx_1_grp {
				pinctrl-single,pins = <0xb4 0x03 0xd040>;
			};

			keypad_0_grp {
				pinctrl-single,pins = <0x23c 0x03 0xb040 0x240 0x03 0xb040 0x244 0x03 0xb040 0x248 0x03 0xb040 0x24c 0x03 0xb040 0x138 0x06 0xb040 0x13c 0x06 0xb040 0x140 0x06 0xb040>;
			};

			keypad_1_grp {
				pinctrl-single,pins = <0x228 0x05 0xb040 0x22c 0x05 0xb040 0x230 0x05 0xb040 0x234 0x05 0xb040 0x238 0x05 0xb040 0xc4 0x05 0xb040 0xc8 0x05 0xb040 0xcc 0x05 0xb040>;
			};

			direct_key_0_grp {
				pinctrl-single,pins = <0x100 0x05 0xd040 0x104 0x05 0xd040 0x108 0x05 0xd040 0x10c 0x05 0xd040 0x110 0x05 0xd040>;
			};

			direct_key_1_grp {
				pinctrl-single,pins = <0x23c 0x02 0xd040 0x240 0x02 0xd040 0x244 0x02 0xd040 0x248 0x02 0xd040 0x24c 0x02 0xd040>;
			};

			pwm0_0_grp {
				pinctrl-single,pins = <0x1b8 0x05 0xc440>;
			};

			pwm0_1_grp {
				pinctrl-single,pins = <0x3c 0x03 0xd040>;
			};

			pwm0_2_grp {
				pinctrl-single,pins = <0x5c 0x04 0xd040>;
			};

			pwm1_0_grp {
				pinctrl-single,pins = <0x1bc 0x05 0xc440>;
			};

			pwm1_1_grp {
				pinctrl-single,pins = <0x78 0x03 0xd040>;
			};

			pwm1_2_grp {
				pinctrl-single,pins = <0x60 0x04 0xd040>;
			};

			pwm2_0_grp {
				pinctrl-single,pins = <0x1c0 0x05 0xc440>;
			};

			pwm2_1_grp {
				pinctrl-single,pins = <0x5c 0x02 0xd040>;
			};

			pwm2_2_grp {
				pinctrl-single,pins = <0x7c 0x03 0xd040>;
			};

			pwm2_3_grp {
				pinctrl-single,pins = <0x64 0x04 0xd040>;
			};

			pwm3_0_grp {
				pinctrl-single,pins = <0x1c4 0x05 0xc440>;
			};

			pwm3_1_grp {
				pinctrl-single,pins = <0x88 0x03 0xd040>;
			};

			pwm3_2_grp {
				pinctrl-single,pins = <0x68 0x04 0xd040>;
			};

			pwm4_0_grp {
				pinctrl-single,pins = <0x1c8 0x05 0xc440>;
			};

			pwm4_1_grp {
				pinctrl-single,pins = <0x8c 0x03 0xd040>;
				phandle = <0x3c>;
			};

			pwm5_0_grp {
				pinctrl-single,pins = <0x1cc 0x05 0xc440>;
			};

			pwm5_1_grp {
				pinctrl-single,pins = <0x90 0x03 0xd040>;
			};

			pwm6_0_grp {
				pinctrl-single,pins = <0x1f4 0x04 0xd040>;
			};

			pwm6_1_grp {
				pinctrl-single,pins = <0x94 0x03 0xd040>;
			};

			pwm7_0_grp {
				pinctrl-single,pins = <0x204 0x02 0xd040>;
			};

			pwm7_1_grp {
				pinctrl-single,pins = <0x98 0x02 0xd040>;
			};

			pwm8_0_grp {
				pinctrl-single,pins = <0x04 0x03 0xd040>;
			};

			pwm8_1_grp {
				pinctrl-single,pins = <0x9c 0x04 0xd040>;
			};

			pwm9_0_grp {
				pinctrl-single,pins = <0x08 0x03 0xd040>;
			};

			pwm9_1_grp {
				pinctrl-single,pins = <0xa0 0x04 0xd040>;
			};

			pwm10_0_grp {
				pinctrl-single,pins = <0x0c 0x03 0xd040>;
			};

			pwm10_1_grp {
				pinctrl-single,pins = <0xa4 0x04 0xd040>;
			};

			pwm11_0_grp {
				pinctrl-single,pins = <0x10 0x03 0xd040>;
			};

			pwm11_1_grp {
				pinctrl-single,pins = <0xa8 0x04 0xd040>;
			};

			pwm12_0_grp {
				pinctrl-single,pins = <0x14 0x03 0xd040>;
			};

			pwm12_1_grp {
				pinctrl-single,pins = <0xac 0x04 0xd040>;
			};

			pwm13_0_grp {
				pinctrl-single,pins = <0x18 0x03 0xd040>;
			};

			pwm13_1_grp {
				pinctrl-single,pins = <0xb0 0x04 0xd040>;
			};

			pwm14_0_grp {
				pinctrl-single,pins = <0x1c 0x03 0xd040>;
			};

			pwm14_1_grp {
				pinctrl-single,pins = <0xb4 0x04 0xd040>;
				phandle = <0x3d>;
			};

			pwm15_0_grp {
				pinctrl-single,pins = <0x20 0x03 0xd040>;
			};

			pwm15_1_grp {
				pinctrl-single,pins = <0xb8 0x04 0xd040>;
			};

			pwm16_0_grp {
				pinctrl-single,pins = <0x28 0x03 0xd040>;
			};

			pwm16_1_grp {
				pinctrl-single,pins = <0xbc 0x04 0xd040>;
			};

			pwm17_0_grp {
				pinctrl-single,pins = <0x2c 0x03 0xd040>;
			};

			pwm17_1_grp {
				pinctrl-single,pins = <0xd8 0x02 0xd040>;
			};

			pwm18_0_grp {
				pinctrl-single,pins = <0x30 0x03 0xd040>;
			};

			pwm18_1_grp {
				pinctrl-single,pins = <0xe8 0x04 0xd040>;
			};

			pwm19_0_grp {
				pinctrl-single,pins = <0x38 0x03 0xd040>;
			};

			pwm19_1_grp {
				pinctrl-single,pins = <0x100 0x04 0xd040>;
			};

			rpwm2_0_grp {
				pinctrl-single,pins = <0x140 0x02 0xc440>;
			};

			rpwm9_0_grp {
				pinctrl-single,pins = <0x12c 0x02 0xd040>;
			};

			sspa0_0_grp {
				pinctrl-single,pins = <0x228 0x03 0xc040 0x22c 0x03 0xc040 0x230 0x03 0xc040 0x234 0x03 0xc040 0x238 0x03 0xc040>;
			};

			sspa0_1_grp {
				pinctrl-single,pins = <0xec 0x02 0xc040 0x20c 0x02 0xc040 0x210 0x02 0xc040 0x214 0x02 0xc040 0x218 0x02 0xc040>;
			};

			sspa1_grp {
				pinctrl-single,pins = <0x64 0x03 0xc040 0x68 0x01 0xc040 0x6c 0x01 0xc040 0x70 0x01 0xc040 0x74 0x01 0xc040>;
			};

			ssp2_0_grp {
				pinctrl-single,pins = <0x130 0x01 0x440 0x134 0x01 0xc440 0x138 0x01 0x440 0x13c 0x01 0x440>;
			};

			ssp2_1_grp {
				pinctrl-single,pins = <0x104 0x03 0x440 0x108 0x03 0xc440 0x10c 0x03 0x440 0x110 0x03 0x440>;
			};

			ssp3_0_grp {
				pinctrl-single,pins = <0x130 0x02 0x440 0x134 0x02 0xc440 0x138 0x02 0x440 0x13c 0x02 0x440>;
				phandle = <0x2e>;
			};

			ssp3_1_grp {
				pinctrl-single,pins = <0xf0 0x02 0x1040 0xf4 0x02 0xd040 0xf8 0x02 0x1040 0xfc 0x02 0x1040>;
			};

			qspi_grp {
				pinctrl-single,pins = <0x174 0x00 0x440 0x170 0x00 0x440 0x16c 0x00 0x440 0x168 0x00 0x440 0x17c 0x00 0x440 0x178 0x00 0xc440>;
				phandle = <0x5b>;
			};

			mmc1_grp {
				pinctrl-single,pins = <0x1b8 0x00 0xc440 0x1bc 0x00 0xc440 0x1c0 0x00 0xc440 0x1c4 0x00 0xc440 0x1c8 0x00 0xc440 0x1cc 0x00 0xa440>;
				phandle = <0x4d>;
			};

			mmc1_fast_grp {
				pinctrl-single,pins = <0x1b8 0x00 0xd840 0x1bc 0x00 0xd840 0x1c0 0x00 0xd840 0x1c4 0x00 0xd840 0x1c8 0x00 0xd840 0x1cc 0x00 0xb840>;
				phandle = <0x4e>;
			};

			mmc2_grp {
				pinctrl-single,pins = <0x40 0x01 0xd040 0x44 0x01 0xd040 0x48 0x01 0xd040 0x4c 0x01 0xd040 0x50 0x01 0xd040 0x54 0x01 0xd040>;
				phandle = <0x51>;
			};

			usb0_0_grp {
				pinctrl-single,pins = <0x244 0x01 0xb040 0x248 0x01 0xb040 0x24c 0x01 0xb040>;
			};

			usb0_1_grp {
				pinctrl-single,pins = <0x104 0x01 0xb040 0x108 0x01 0xd040 0x100 0x01 0xb040>;
			};

			usb1_0_grp {
				pinctrl-single,pins = <0x240 0x01 0xb040>;
			};

			usb1_1_grp {
				pinctrl-single,pins = <0x10c 0x01 0xb040>;
			};

			usb2_0_grp {
				pinctrl-single,pins = <0x234 0x02 0xb040 0x238 0x02 0xb040 0x23c 0x01 0xb040>;
			};

			usb2_1_grp {
				pinctrl-single,pins = <0x114 0x01 0xb040 0x118 0x01 0xd040 0x110 0x01 0xb040>;
			};

			pcie0_0_grp {
				pinctrl-single,pins = <0x40 0x02 0x1040 0x44 0x02 0x1040 0x48 0x02 0x1040>;
			};

			pcie0_1_grp {
				pinctrl-single,pins = <0x78 0x04 0x1040 0x7c 0x04 0x1040 0x80 0x04 0x1040>;
			};

			pcie0_2_grp {
				pinctrl-single,pins = <0x1d0 0x04 0x1040 0x21c 0x04 0x1040 0x220 0x04 0x1040>;
			};

			pcie0_3_grp {
				pinctrl-single,pins = <0xd8 0x03 0x1040 0xdc 0x03 0x1040 0xe0 0x03 0x1040>;
			};

			pcie1_0_grp {
				pinctrl-single,pins = <0x40 0x04 0x1040 0x44 0x04 0x1040 0x48 0x04 0x1040>;
			};

			pcie1_1_grp {
				pinctrl-single,pins = <0x84 0x04 0x1040 0x88 0x04 0x1040 0x8c 0x04 0x1040>;
			};

			pcie1_2_grp {
				pinctrl-single,pins = <0xe4 0x03 0x1040 0xe8 0x03 0x1040 0xec 0x03 0x1040>;
			};

			pcie1_3_grp {
				pinctrl-single,pins = <0xf0 0x04 0x1040 0xf4 0x04 0x1040 0xf8 0x04 0x1040>;
				phandle = <0x57>;
			};

			pcie2_0_grp {
				pinctrl-single,pins = <0x4c 0x04 0x1040 0x50 0x04 0x1040 0x54 0x04 0x1040>;
			};

			pcie2_1_grp {
				pinctrl-single,pins = <0x90 0x04 0x1040 0x94 0x04 0x1040 0x98 0x04 0x1040>;
			};

			pcie2_2_grp {
				pinctrl-single,pins = <0xfc 0x04 0x1040 0x12c 0x04 0x1040 0x224 0x04 0x1040>;
			};

			pcie2_3_grp {
				pinctrl-single,pins = <0x20c 0x03 0x1040 0x210 0x03 0x1040 0x214 0x03 0x1040>;
			};

			pcie2_4_grp {
				pinctrl-single,pins = <0xfc 0x04 0x1040 0x210 0x03 0x1040 0x224 0x04 0x1040>;
			};

			gmac0_grp {
				pinctrl-single,pins = <0x04 0x01 0x1040 0x08 0x01 0x1040 0x0c 0x01 0x1040 0x10 0x01 0x1040 0x14 0x01 0x1040 0x18 0x01 0x1040 0x1c 0x01 0x1040 0x20 0x01 0x1040 0x24 0x01 0x1040 0x28 0x01 0x1040 0x2c 0x01 0x1040 0x30 0x01 0x1040 0x34 0x01 0x40 0x38 0x01 0x40 0x3c 0x01 0x1040 0xb8 0x01 0x1040>;
				phandle = <0x43>;
			};

			gmac1_grp {
				pinctrl-single,pins = <0x78 0x01 0x1040 0x7c 0x01 0x1040 0x80 0x01 0x1040 0x84 0x01 0x1040 0x88 0x01 0x1040 0x8c 0x01 0x1040 0x90 0x01 0x40 0x94 0x01 0x40 0x98 0x01 0x1040 0x9c 0x01 0x40 0xa0 0x01 0x40 0xa4 0x01 0x40 0xa8 0x01 0x40 0xac 0x01 0x40 0xb0 0x01 0x1040 0xbc 0x01 0x1040>;
			};

			can_0_grp {
				pinctrl-single,pins = <0x130 0x03 0xc440 0x134 0x03 0xc440>;
			};

			can_1_grp {
				pinctrl-single,pins = <0xdc 0x02 0xd040 0xe0 0x02 0xd040>;
			};

			r_can_0_grp {
				pinctrl-single,pins = <0xc0 0x02 0xd040 0xc4 0x02 0xd040>;
			};

			r_can_1_grp {
				pinctrl-single,pins = <0x1d0 0x01 0xd040 0x21c 0x01 0xd040>;
			};

			hdmi_0_grp {
				pinctrl-single,pins = <0x1ec 0x01 0xd040 0x1f0 0x01 0xd040 0x1f4 0x01 0xb040 0x1f8 0x01 0xb040>;
				phandle = <0x6d>;
			};

			hdmi_1_grp {
				pinctrl-single,pins = <0xf0 0x01 0xd040 0xf4 0x01 0xd040 0xf8 0x01 0xb040 0xfc 0x01 0xb040>;
			};

			spi_lcd_0_grp {
				pinctrl-single,pins = <0x1ec 0x03 0x1040 0x1f0 0x03 0x1040 0x1f4 0x03 0x1040 0x1f8 0x03 0x1040 0x1fc 0x03 0x1040 0x200 0x03 0x1040 0x204 0x03 0x1040>;
			};

			spi_lcd_1_grp {
				pinctrl-single,pins = <0x11c 0x03 0x1040 0x120 0x03 0x1040 0x124 0x03 0x1040 0x128 0x03 0x1040 0x12c 0x03 0x1040 0x218 0x03 0x1040 0x100 0x03 0x1040>;
			};

			camera0_grp {
				pinctrl-single,pins = <0xd8 0x01 0x1040>;
				phandle = <0x78>;
			};

			camera1_grp {
				pinctrl-single,pins = <0xec 0x01 0x1040>;
				phandle = <0x7d>;
			};

			camera2_grp {
				pinctrl-single,pins = <0x230 0x01 0x1040>;
			};

			pmic_grp {
				pinctrl-single,pins = <0x1dc 0x00 0xd040 0x1e0 0x00 0xb040 0x1e4 0x00 0xb040>;
			};

			mn_clk_0_grp {
				pinctrl-single,pins = <0x204 0x01 0x1040>;
			};

			mn_clk_1_grp {
				pinctrl-single,pins = <0x148 0x04 0x1040>;
			};

			mn_clk_2_grp {
				pinctrl-single,pins = <0xb4 0x01 0x1040>;
			};

			mn_clk_3_grp {
				pinctrl-single,pins = <0x54 0x03 0x1040>;
			};

			mn_clk_4_grp {
				pinctrl-single,pins = <0x60 0x03 0x1040>;
			};

			mn_clk_5_grp {
				pinctrl-single,pins = <0x84 0x03 0x1040>;
			};

			mn_clk2_0_grp {
				pinctrl-single,pins = <0x200 0x01 0x1040>;
			};

			mn_clk2_1_grp {
				pinctrl-single,pins = <0x158 0x03 0x1040>;
			};

			vcxo_0_grp {
				pinctrl-single,pins = <0x1e0 0x03 0x1040 0x1e4 0x03 0x1040>;
			};

			vcxo_1_grp {
				pinctrl-single,pins = <0x44 0x03 0x1040 0x48 0x03 0x1040>;
			};

			vcxo_2_grp {
				pinctrl-single,pins = <0x1f8 0x04 0x1040 0x1fc 0x04 0x1040>;
			};

			vcxo_out_0_grp {
				pinctrl-single,pins = <0x200 0x02 0x1040>;
			};

			vcxo_out_1_grp {
				pinctrl-single,pins = <0x34 0x03 0x1040>;
			};

			32k_out_0_grp {
				pinctrl-single,pins = <0x58 0x03 0x1040>;
			};

			32k_out_1_grp {
				pinctrl-single,pins = <0x80 0x03 0x1040>;
			};

			32k_out_2_grp {
				pinctrl-single,pins = <0x74 0x04 0x1040>;
			};

			pri_grp {
				pinctrl-single,pins = <0x11c 0x00 0xd040 0x120 0x00 0xd040 0x124 0x00 0xd040 0x128 0x00 0xd040>;
			};

			pinctrl_rcpu_grp {
				pinctrl-single,pins = <0xc0 0x01 0xc440 0xc4 0x01 0xc440>;
				phandle = <0x2d>;
			};

			rpwm7_0_grp {
				pinctrl-single,pins = <0xd4 0x03 0xc440>;
				phandle = <0x3e>;
			};

			wlan_wakeup_grp {
				pinctrl-single,pins = <0x10c 0x00 0xb020>;
				phandle = <0x89>;
			};

			sspa0_2_grp {
				pinctrl-single,pins = <0x20c 0x02 0xc040 0x210 0x02 0xc040 0x230 0x03 0xc040 0x234 0x03 0xc040 0x238 0x03 0xc040>;
				phandle = <0x81>;
			};

			pcie2_5_grp {
				pinctrl-single,pins = <0xfc 0x04 0x1040 0x94 0x04 0x1040 0x224 0x04 0x1040>;
				phandle = <0x5a>;
			};
		};

		power-management@0 {
			compatible = "simple-bus";
			#address-cells = <0x02>;
			#size-cells = <0x02>;
			ranges;

			mpmu@1 {
				compatible = "simple-mfd\0spacemit,spacemit-mpmu\0syscon";
				reg = <0x00 0xd4050000 0x00 0x3004>;
			};

			apmu@2 {
				compatible = "simple-mfd\0spacemit,spacemit-apmu\0syscon";
				reg = <0x00 0xd4282800 0x00 0x400>;
			};

			power-controller {
				compatible = "spacemit,power-controller";
				#power-domain-cells = <0x01>;
				#address-cells = <0x01>;
				#size-cells = <0x00>;
				domains = <0x09>;
				phandle = <0x20>;

				power-domain@SPT_PD_BUS {
					reg = <0x00>;
					pm_qos = <0x07>;
					#power-domain-cells = <0x00>;
				};

				power-domain@SPT_PD_VPU {
					reg = <0x01>;
					pm_qos = <0x0c>;
					reg_pwr_ctrl = <0xa8>;
					bit_sleep2 = <0x03>;
					bit_sleep1 = <0x02>;
					bit_isolation = <0x01>;
					bit_pwr_stat = <0x01>;
					bit_hw_pwr_stat = <0x09>;
					#power-domain-cells = <0x00>;
				};

				power-domain@SPT_PD_GPU {
					reg = <0x02>;
					pm_qos = <0x0c>;
					reg_pwr_ctrl = <0xd0>;
					bit_sleep2 = <0x03>;
					bit_sleep1 = <0x02>;
					bit_isolation = <0x01>;
					bit_pwr_stat = <0x00>;
					#power-domain-cells = <0x00>;
				};

				power-domain@SPT_PD_LCD {
					reg = <0x03>;
					pm_qos = <0x0c>;
					reg_pwr_ctrl = <0x380>;
					bit_hw_mode = <0x04>;
					bit_sleep2 = <0x03>;
					bit_sleep1 = <0x02>;
					bit_isolation = <0x01>;
					bit_auto_pwr_on = <0x00>;
					bit_pwr_stat = <0x04>;
					bit_hw_pwr_stat = <0x0c>;
					use_hw = <0x01>;
					#power-domain-cells = <0x00>;
				};

				power-domain@SPT_PD_ISP {
					reg = <0x04>;
					pm_qos = <0x0c>;
					reg_pwr_ctrl = <0x37c>;
					bit_hw_mode = <0x04>;
					bit_sleep2 = <0x03>;
					bit_sleep1 = <0x02>;
					bit_isolation = <0x01>;
					bit_auto_pwr_on = <0x00>;
					bit_pwr_stat = <0x02>;
					bit_hw_pwr_stat = <0x0a>;
					#power-domain-cells = <0x00>;
				};

				power-domain@SPT_PD_AUDIO {
					reg = <0x05>;
					pm_qos = <0x0f>;
					reg_pwr_ctrl = <0x378>;
					bit_hw_mode = <0x04>;
					bit_sleep2 = <0x03>;
					bit_sleep1 = <0x02>;
					bit_isolation = <0x01>;
					bit_auto_pwr_on = <0x00>;
					bit_pwr_stat = <0x03>;
					bit_hw_pwr_stat = <0x0b>;
					use_hw = <0x01>;
					#power-domain-cells = <0x00>;
				};

				power-domain@SPT_PD_GNSS {
					reg = <0x06>;
					pm_qos = <0x0f>;
					reg_pwr_ctrl = <0x13c>;
					bit_hw_mode = <0x04>;
					bit_sleep2 = <0x03>;
					bit_sleep1 = <0x02>;
					bit_isolation = <0x01>;
					bit_auto_pwr_on = <0x00>;
					bit_pwr_stat = <0x06>;
					bit_hw_pwr_stat = <0x0e>;
					#power-domain-cells = <0x00>;
				};

				power-domain@SPT_PD_HDMI {
					reg = <0x07>;
					pm_qos = <0x0c>;
					reg_pwr_ctrl = <0x3f4>;
					bit_hw_mode = <0x04>;
					bit_sleep2 = <0x03>;
					bit_sleep1 = <0x02>;
					bit_isolation = <0x01>;
					bit_auto_pwr_on = <0x00>;
					bit_pwr_stat = <0x07>;
					bit_hw_pwr_stat = <0x0f>;
					use_hw = <0x01>;
					#power-domain-cells = <0x00>;
				};

				power-domain@SPT_PD_DUMMY {
					reg = <0x08>;
					pm_qos = <0x0f>;
					#power-domain-cells = <0x00>;
				};
			};
		};

		serial@d4017000 {
			compatible = "spacemit,pxa-uart";
			reg = <0x00 0xd4017000 0x00 0x100>;
			interrupt-parent = <0x1e>;
			interrupts = <0x2a>;
			clocks = <0x03 0x3a 0x03 0xb4>;
			clock-names = "func\0gate";
			clk-fpga = <0xe11130>;
			resets = <0x1d 0x01>;
			power-domains = <0x20 0x00>;
			clk,pm-runtime,no-sleep;
			cpuidle,pm-runtime,sleep;
			dmas = <0x21 0x04 0x01 0x21 0x03 0x01>;
			dma-names = "rx\0tx";
			interconnects = <0x22>;
			interconnect-names = "dma-mem";
			reg-shift = <0x02>;
			reg-io-width = <0x04>;
			status = "okay";
			pinctrl-names = "default";
			pinctrl-0 = <0x23>;
		};

		uart@f0612000 {
			compatible = "spacemit,pxa-uart";
			reg = <0x00 0xf0612000 0x00 0x100>;
			interrupt-parent = <0x1e>;
			interrupts = <0x2b>;
			clocks = <0x03 0xa9 0x03 0xb4>;
			clock-names = "func\0gate";
			resets = <0x1d 0x5f>;
			power-domains = <0x20 0x00>;
			clk,pm-runtime,no-sleep;
			cpuidle,pm-runtime,sleep;
			interconnects = <0x22>;
			interconnect-names = "dma-mem";
			status = "disabled";
		};

		uart@d4017100 {
			compatible = "spacemit,pxa-uart";
			reg = <0x00 0xd4017100 0x00 0x100>;
			interrupt-parent = <0x1e>;
			interrupts = <0x2c>;
			clocks = <0x03 0x3b 0x03 0xb4>;
			clock-names = "func\0gate";
			clk-fpga = <0xe11130>;
			resets = <0x1d 0x02>;
			power-domains = <0x20 0x00>;
			clk,pm-runtime,no-sleep;
			cpuidle,pm-runtime,sleep;
			interconnects = <0x22>;
			interconnect-names = "dma-mem";
			status = "okay";
			pinctrl-names = "default";
			pinctrl-0 = <0x24>;
		};

		uart@d4017200 {
			compatible = "spacemit,pxa-uart";
			reg = <0x00 0xd4017200 0x00 0x100>;
			interrupt-parent = <0x1e>;
			interrupts = <0x2d>;
			clocks = <0x03 0x3c 0x03 0xb4>;
			clock-names = "func\0gate";
			clk-fpga = <0xe11130>;
			resets = <0x1d 0x19>;
			power-domains = <0x20 0x00>;
			clk,pm-runtime,no-sleep;
			cpuidle,pm-runtime,sleep;
			interconnects = <0x22>;
			interconnect-names = "dma-mem";
			status = "disabled";
		};

		uart@d4017300 {
			compatible = "spacemit,pxa-uart";
			interrupt-parent = <0x1e>;
			reg = <0x00 0xd4017300 0x00 0x100>;
			interrupts = <0x2e>;
			clocks = <0x03 0x3d 0x03 0xb4>;
			clock-names = "func\0gate";
			clk-fpga = <0xe11130>;
			resets = <0x1d 0x2d>;
			power-domains = <0x20 0x00>;
			clk,pm-runtime,no-sleep;
			cpuidle,pm-runtime,sleep;
			interconnects = <0x22>;
			interconnect-names = "dma-mem";
			pinctrl-names = "default";
			pinctrl-0 = <0x92>;
			status = "okay";
		};

		uart@d4017400 {
			compatible = "spacemit,pxa-uart";
			interrupt-parent = <0x1e>;
			reg = <0x00 0xd4017400 0x00 0x100>;
			interrupts = <0x2f>;
			clocks = <0x03 0x3e 0x03 0xb4>;
			clock-names = "func\0gate";
			clk-fpga = <0xe11130>;
			resets = <0x1d 0x2e>;
			power-domains = <0x20 0x00>;
			clk,pm-runtime,no-sleep;
			cpuidle,pm-runtime,sleep;
			interconnects = <0x22>;
			interconnect-names = "dma-mem";
			pinctrl-names = "default";
			pinctrl-0 = <0x91>;
			status = "okay";
		};

		uart@d4017500 {
			compatible = "spacemit,pxa-uart";
			interrupt-parent = <0x1e>;
			reg = <0x00 0xd4017500 0x00 0x100>;
			interrupts = <0x30>;
			clocks = <0x03 0x3f 0x03 0xb4>;
			clock-names = "func\0gate";
			clk-fpga = <0xe11130>;
			resets = <0x1d 0x2f>;
			power-domains = <0x20 0x00>;
			clk,pm-runtime,no-sleep;
			cpuidle,pm-runtime,sleep;
			interconnects = <0x22>;
			interconnect-names = "dma-mem";
			status = "disabled";
		};

		uart@d4017600 {
			compatible = "spacemit,pxa-uart";
			interrupt-parent = <0x1e>;
			reg = <0x00 0xd4017600 0x00 0x100>;
			interrupts = <0x31>;
			clocks = <0x03 0x40 0x03 0xb4>;
			clock-names = "func\0gate";
			clk-fpga = <0xe11130>;
			resets = <0x1d 0x30>;
			power-domains = <0x20 0x00>;
			clk,pm-runtime,no-sleep;
			cpuidle,pm-runtime,sleep;
			interconnects = <0x22>;
			interconnect-names = "dma-mem";
			status = "disabled";
		};

		uart@d4017700 {
			compatible = "spacemit,pxa-uart";
			interrupt-parent = <0x1e>;
			reg = <0x00 0xd4017700 0x00 0x100>;
			interrupts = <0x32>;
			clocks = <0x03 0x41 0x03 0xb4>;
			clock-names = "func\0gate";
			clk-fpga = <0xe11130>;
			resets = <0x1d 0x31>;
			power-domains = <0x20 0x00>;
			clk,pm-runtime,no-sleep;
			cpuidle,pm-runtime,sleep;
			interconnects = <0x22>;
			interconnect-names = "dma-mem";
			status = "disabled";
		};

		uart@d4017800 {
			compatible = "spacemit,pxa-uart";
			interrupt-parent = <0x1e>;
			reg = <0x00 0xd4017800 0x00 0x100>;
			interrupts = <0x33>;
			clocks = <0x03 0x42 0x03 0xb4>;
			clock-names = "func\0gate";
			clk-fpga = <0xe11130>;
			resets = <0x1d 0x32>;
			power-domains = <0x20 0x00>;
			clk,pm-runtime,no-sleep;
			cpuidle,pm-runtime,sleep;
			interconnects = <0x22>;
			interconnect-names = "dma-mem";
			status = "disabled";
		};

		r_uart0@c0881000 {
			compatible = "spacemit,rcpu-pxa-uart0";
			reg = <0x00 0xc0881000 0x00 0x100>;
			clocks = <0x03 0xbd 0x03 0xb4>;
			clock-names = "func\0gate";
			resets = <0x1d 0x6b>;
			power-domains = <0x20 0x00>;
			clk,pm-runtime,no-sleep;
			cpuidle,pm-runtime,sleep;
			rcpu-uart;
			interconnects = <0x22>;
			interconnect-names = "dma-mem";
			reg-shift = <0x02>;
			reg-io-width = <0x04>;
			status = "okay";
		};

		r_uart1@c088d000 {
			compatible = "spacemit,rcpu-pxa-uart1";
			reg = <0x00 0xc088d000 0x00 0x100>;
			clocks = <0x03 0xbe 0x03 0xb4>;
			clock-names = "func\0gate";
			resets = <0x1d 0x6c>;
			power-domains = <0x20 0x00>;
			clk,pm-runtime,no-sleep;
			cpuidle,pm-runtime,sleep;
			rcpu-uart;
			interconnects = <0x22>;
			interconnect-names = "dma-mem";
			reg-shift = <0x02>;
			reg-io-width = <0x04>;
			status = "disabled";
		};

		mailbox@d4013400 {
			compatible = "spacemit,k1-x-mailbox";
			reg = <0x00 0xd4013400 0x00 0x100>;
			interrupt-parent = <0x1e>;
			interrupts = <0x34>;
			#mbox-cells = <0x01>;
			clocks = <0x03 0x6b>;
			clock-names = "core";
			resets = <0x1d 0x2c>;
			reset-names = "core_reset";
			power-domains = <0x20 0x08>;
			status = "okay";
			phandle = <0x25>;
		};

		rcpu_rproc@0 {
			compatible = "spacemit,k1-x-rproc";
			reg = <0x00 0xc088c000 0x00 0x1000 0x00 0xc0880000 0x00 0x200>;
			ddr-remap-base = <0x100000>;
			esos-entry-point = <0x30300114>;
			clocks = <0x03 0x97 0x03 0xd4>;
			clock-names = "core\0apb";
			apb-clk-rate = "\aS\0";
			resets = <0x1d 0x58>;
			reset-names = "core_reset";
			mboxes = <0x25 0x00 0x25 0x01>;
			mbox-names = "vq0\0vq1";
			firmware-name = "esos.elf";
			power-domains = <0x20 0x05>;
			interconnects = <0x26>;
			interconnect-names = "dma-mem";
			memory-region = <0x27 0x28 0x29 0x2a 0x2b 0x2c>;
			status = "okay";
			pinctrl-names = "default";
			pinctrl-0 = <0x2d>;
		};

		pdma@d4000000 {
			compatible = "spacemit,pdma-1.0";
			reg = <0x00 0xd4000000 0x00 0x4000>;
			interrupts = <0x48>;
			interrupt-parent = <0x1e>;
			clocks = <0x03 0x91>;
			resets = <0x1d 0x50>;
			#dma-cells = <0x02>;
			#dma-channels = <0x10>;
			max-burst-size = <0x40>;
			reserved-channels = <0x0f 0x2d>;
			power-domains = <0x20 0x00>;
			clk,pm-runtime,no-sleep;
			cpuidle,pm-runtime,sleep;
			interconnects = <0x22>;
			interconnect-names = "dma-mem";
			status = "ok";
			phandle = <0x21>;
		};

		adma@C0883800 {
			compatible = "spacemit,k1x-adma";
			reg = <0x00 0xc0883800 0x00 0x100 0x00 0xc0882050 0x00 0x04 0x00 0xc08d0000 0x00 0x400>;
			reg-names = "adma_reg\0ctrl_reg\0buf_addr";
			#dma-cells = <0x00>;
			hdmi-sample;
			status = "ok";
			phandle = <0x80>;
		};

		spi@d4026000 {
			compatible = "spacemit,k1x-spi";
			reg = <0x00 0xd4026000 0x00 0x30>;
			k1x,ssp-id = <0x00>;
			k1x,ssp-clock-rate = <0x18cba80>;
			dmas = <0x21 0x16 0x01 0x21 0x15 0x01>;
			dma-names = "rx\0tx";
			power-domains = <0x20 0x00>;
			cpuidle,pm-runtime,sleep;
			interrupt-parent = <0x1e>;
			interrupts = <0x38>;
			clocks = <0x03 0x66>;
			resets = <0x1d 0x20>;
			#address-cells = <0x01>;
			#size-cells = <0x00>;
			interconnects = <0x22>;
			interconnect-names = "dma-mem";
			status = "disabled";
		};

		spi@d4026800 {
			compatible = "spacemit,k1x-spi";
			reg = <0x00 0xd4026800 0x00 0x30>;
			k1x,ssp-id = <0x01>;
			k1x,ssp-clock-rate = <0x18cba80>;
			dmas = <0x21 0x18 0x01 0x21 0x17 0x01>;
			dma-names = "rx\0tx";
			power-domains = <0x20 0x00>;
			cpuidle,pm-runtime,sleep;
			interrupt-parent = <0x1e>;
			interrupts = <0x39>;
			clocks = <0x03 0x67>;
			resets = <0x1d 0x21>;
			#address-cells = <0x01>;
			#size-cells = <0x00>;
			interconnects = <0x22>;
			interconnect-names = "dma-mem";
			status = "disabled";
		};

		spi@f0613000 {
			compatible = "spacemit,k1x-spi";
			reg = <0x00 0xf0613000 0x00 0x34>;
			k1x,ssp-id = <0x02>;
			k1x,ssp-clock-rate = <0x30d4000>;
			k1x,ssp-disable-dma;
			power-domains = <0x20 0x00>;
			cpuidle,pm-runtime,sleep;
			interrupt-parent = <0x1e>;
			interrupts = <0x36>;
			clocks = <0x03 0xaa>;
			resets = <0x1d 0x60>;
			#address-cells = <0x01>;
			#size-cells = <0x00>;
			interconnects = <0x22>;
			interconnect-names = "dma-mem";
			status = "disabled";
		};

		spi@d401c000 {
			compatible = "spacemit,k1x-spi";
			reg = <0x00 0xd401c000 0x00 0x34>;
			k1x,ssp-id = <0x03>;
			k1x,ssp-clock-rate = <0x186a000>;
			dmas = <0x21 0x14 0x01 0x21 0x13 0x01>;
			dma-names = "rx\0tx";
			power-domains = <0x20 0x00>;
			cpuidle,pm-runtime,sleep;
			interrupt-parent = <0x1e>;
			interrupts = <0x37>;
			clocks = <0x03 0x58>;
			resets = <0x1d 0x18>;
			#address-cells = <0x01>;
			#size-cells = <0x00>;
			interconnects = <0x22>;
			interconnect-names = "dma-mem";
			status = "okay";
			pinctrl-names = "default";
			pinctrl-0 = <0x2e>;
			k1x,ssp-disable-dma;
		};

		i2c@d4010800 {
			compatible = "spacemit,k1x-i2c";
			spacemit,adapter-id = <0x00>;
			reg = <0x00 0xd4010800 0x00 0x38>;
			#address-cells = <0x01>;
			#size-cells = <0x00>;
			interrupt-parent = <0x1e>;
			interrupts = <0x24>;
			clocks = <0x03 0x5a>;
			resets = <0x1d 0x1b>;
			spacemit,dma-disable;
			spacemit,i2c-master-code = [0e];
			spacemit,i2c-clk-rate = <0x1e84800>;
			spacemit,i2c-lcr = <0x82c469f>;
			spacemit,i2c-wcr = <0x142a>;
			spacemit,apb_clock = <0x3197500>;
			power-domains = <0x20 0x00>;
			cpuidle,pm-runtime,sleep;
			interconnects = <0x22>;
			interconnect-names = "dma-mem";
			status = "okay";
			pinctrl-names = "default";
			pinctrl-0 = <0x2f>;
			spacemit,i2c-fast-mode;
		};

		i2c@d4011000 {
			compatible = "spacemit,k1x-i2c";
			spacemit,adapter-id = <0x01>;
			reg = <0x00 0xd4011000 0x00 0x38>;
			#address-cells = <0x01>;
			#size-cells = <0x00>;
			interrupt-parent = <0x1e>;
			interrupts = <0x25>;
			clocks = <0x03 0x5b>;
			resets = <0x1d 0x24>;
			spacemit,dma-disable;
			spacemit,i2c-master-code = [0e];
			spacemit,i2c-clk-rate = <0x1e84800>;
			spacemit,i2c-lcr = <0x82c469f>;
			spacemit,i2c-wcr = <0x142a>;
			spacemit,apb_clock = <0x3197500>;
			power-domains = <0x20 0x00>;
			cpuidle,pm-runtime,sleep;
			interconnects = <0x22>;
			interconnect-names = "dma-mem";
			status = "okay";
			pinctrl-names = "default";
			pinctrl-0 = <0x30>;
			spacemit,i2c-fast-mode;
		};

		i2c@d4012000 {
			compatible = "spacemit,k1x-i2c";
			spacemit,adapter-id = <0x02>;
			reg = <0x00 0xd4012000 0x00 0x38>;
			#address-cells = <0x01>;
			#size-cells = <0x00>;
			interrupt-parent = <0x1e>;
			interrupts = <0x26>;
			clocks = <0x03 0x5c>;
			resets = <0x1d 0x26>;
			spacemit,dma-disable;
			spacemit,i2c-master-code = [0e];
			spacemit,i2c-clk-rate = <0x1e84800>;
			spacemit,i2c-lcr = <0x82c469f>;
			spacemit,i2c-wcr = <0x142a>;
			spacemit,apb_clock = <0x3197500>;
			power-domains = <0x20 0x00>;
			cpuidle,pm-runtime,sleep;
			interconnects = <0x22>;
			interconnect-names = "dma-mem";
			status = "okay";
			pinctrl-names = "default";
			pinctrl-0 = <0x31>;
			spacemit,i2c-fast-mode;

			eeprom@50 {
				compatible = "atmel,24c02";
				reg = <0x50>;
				#address-cells = <0x01>;
				#size-cells = <0x01>;
				power-domains = <0x20 0x08>;
				status = "disabled";

				mac_address0@0 {
					reg = <0x00 0x06>;
					phandle = <0x44>;
				};

				mac_address1@6 {
					reg = <0x06 0x06>;
				};
			};

			es8326@19 {
				compatible = "everest,es8326";
				reg = <0x19>;
				#sound-dai-cells = <0x00>;
				interrupt-parent = <0x32>;
				interrupts = <0x7e 0x01>;
				everest,mic1-src = [44];
				everest,mic2-src = [66];
				status = "okay";
				phandle = <0x87>;
			};
		};

		i2c@f0614000 {
			compatible = "spacemit,k1x-i2c";
			spacemit,adapter-id = <0x03>;
			reg = <0x00 0xf0614000 0x00 0x38>;
			#address-cells = <0x01>;
			#size-cells = <0x00>;
			interrupt-parent = <0x1e>;
			interrupts = <0x27>;
			clocks = <0x03 0xab>;
			resets = <0x1d 0x61>;
			spacemit,dma-disable;
			spacemit,i2c-master-code = [0e];
			spacemit,i2c-clk-rate = <0x1e84800>;
			spacemit,i2c-lcr = <0x82c469f>;
			spacemit,i2c-wcr = <0x142a>;
			spacemit,apb_clock = <0x3197500>;
			power-domains = <0x20 0x00>;
			cpuidle,pm-runtime,sleep;
			interconnects = <0x22>;
			interconnect-names = "dma-mem";
			status = "okay";
			pinctrl-names = "default";
			pinctrl-0 = <0x33>;
		};

		i2c@d4012800 {
			compatible = "spacemit,k1x-i2c";
			spacemit,adapter-id = <0x04>;
			reg = <0x00 0xd4012800 0x00 0x38>;
			#address-cells = <0x01>;
			#size-cells = <0x00>;
			interrupt-parent = <0x1e>;
			interrupts = <0x28>;
			clocks = <0x03 0x5d>;
			resets = <0x1d 0x27>;
			spacemit,dma-disable;
			spacemit,i2c-master-code = [0e];
			spacemit,i2c-clk-rate = <0x1e84800>;
			spacemit,i2c-lcr = <0x82c469f>;
			spacemit,i2c-wcr = <0x142a>;
			spacemit,apb_clock = <0x3197500>;
			power-domains = <0x20 0x00>;
			cpuidle,pm-runtime,sleep;
			interconnects = <0x22>;
			interconnect-names = "dma-mem";
			status = "okay";
			pinctrl-names = "default";
			pinctrl-0 = <0x34>;
		};

		i2c@d4013800 {
			compatible = "spacemit,k1x-i2c";
			spacemit,adapter-id = <0x05>;
			reg = <0x00 0xd4013800 0x00 0x38>;
			#address-cells = <0x01>;
			#size-cells = <0x00>;
			interrupt-parent = <0x1e>;
			interrupts = <0x29>;
			clocks = <0x03 0x5e>;
			resets = <0x1d 0x28>;
			spacemit,dma-disable;
			spacemit,i2c-master-code = [0e];
			spacemit,i2c-clk-rate = <0x1e84800>;
			spacemit,i2c-lcr = <0x82c469f>;
			spacemit,i2c-wcr = <0x142a>;
			spacemit,apb_clock = <0x3197500>;
			power-domains = <0x20 0x00>;
			cpuidle,pm-runtime,sleep;
			interconnects = <0x22>;
			interconnect-names = "dma-mem";
			status = "okay";
			pinctrl-names = "default";
			pinctrl-0 = <0x35>;

			raspits-panel@45 {
				status = "okay";
				compatible = "raspberrypi,7inch-touchscreen-panel";
				reg = <0x45>;
				enable-gpio = <0x32 0x53 0x00>;

				port {

					endpoint {
						remote-endpoint = <0x36>;
						phandle = <0x74>;
					};
				};
			};

			raspits-touch-ft5426@38 {
				status = "okay";
				compatible = "raspits_ft5426";
				reg = <0x38>;
			};
		};

		i2c@d4018800 {
			compatible = "spacemit,k1x-i2c";
			spacemit,adapter-id = <0x06>;
			reg = <0x00 0xd4018800 0x00 0x38>;
			#address-cells = <0x01>;
			#size-cells = <0x00>;
			interrupt-parent = <0x1e>;
			interrupts = <0x46>;
			clocks = <0x03 0x5f>;
			resets = <0x1d 0x29>;
			spacemit,dma-disable;
			spacemit,i2c-master-code = [0e];
			spacemit,i2c-clk-rate = <0x1e84800>;
			spacemit,i2c-lcr = <0x82c469f>;
			spacemit,i2c-wcr = <0x142a>;
			spacemit,apb_clock = <0x3197500>;
			power-domains = <0x20 0x00>;
			cpuidle,pm-runtime,sleep;
			interconnects = <0x22>;
			interconnect-names = "dma-mem";
			status = "disabled";
			pinctrl-names = "default";
			pinctrl-0 = <0x37>;

			gt9xx@5d {
				compatible = "goodix,gt9xx";
				reg = <0x5d>;
				reset-gpios = <0x32 0x72 0x00>;
				irq-gpios = <0x32 0x3a 0x00>;
				irq-flags = <0x02>;
				touchscreen-max-id = <0x0b>;
				touchscreen-size-x = <0x4b0>;
				touchscreen-size-y = <0x780>;
				touchscreen-max-w = <0x200>;
				touchscreen-max-p = <0x200>;
				goodix,int-sync = <0x01>;
				status = "disabled";
			};
		};

		i2c@d401d000 {
			compatible = "spacemit,k1x-i2c";
			spacemit,adapter-id = <0x07>;
			reg = <0x00 0xd401d000 0x00 0x38>;
			#address-cells = <0x01>;
			#size-cells = <0x00>;
			interrupt-parent = <0x1e>;
			interrupts = <0x12>;
			clocks = <0x03 0x60>;
			resets = <0x1d 0x2a>;
			spacemit,dma-disable;
			spacemit,i2c-master-code = [0e];
			spacemit,i2c-clk-rate = <0x1e84800>;
			spacemit,i2c-lcr = <0x82c469f>;
			spacemit,i2c-wcr = <0x142a>;
			spacemit,apb_clock = <0x3197500>;
			power-domains = <0x20 0x00>;
			cpuidle,pm-runtime,sleep;
			interconnects = <0x22>;
			interconnect-names = "dma-mem";
			status = "disabled";
			pinctrl-names = "default";
			pinctrl-0 = <0x38>;
		};

		i2c@d401d800 {
			compatible = "spacemit,k1x-i2c";
			spacemit,adapter-id = <0x08>;
			reg = <0x00 0xd401d800 0x00 0x38>;
			#address-cells = <0x01>;
			#size-cells = <0x00>;
			interrupt-parent = <0x1e>;
			interrupts = <0x13>;
			clocks = <0x03 0x61>;
			resets = <0x1d 0x2b>;
			spacemit,dma-disable;
			spacemit,i2c-master-code = [0e];
			spacemit,i2c-clk-rate = <0x1e84800>;
			spacemit,i2c-lcr = <0x82c469f>;
			spacemit,i2c-wcr = <0x142a>;
			spacemit,apb_clock = <0x3197500>;
			power-domains = <0x20 0x00>;
			cpuidle,pm-runtime,sleep;
			interconnects = <0x22>;
			interconnect-names = "dma-mem";
			status = "okay";
			pinctrl-names = "default";
			pinctrl-0 = <0x39>;

			spm8821@41 {
				compatible = "spacemit,spm8821";
				reg = <0x41>;
				interrupt-parent = <0x1e>;
				interrupts = <0x40>;
				status = "okay";
				vcc_sys-supply = <0x3a>;
				dcdc5-supply = <0x3b>;

				regulators {
					compatible = "pmic,regulator,spm8821";

					DCDC_REG1 {
						regulator-name = "dcdc1";
						regulator-min-microvolt = <0x7a120>;
						regulator-max-microvolt = <0x34a490>;
						regulator-ramp-delay = <0x1388>;
						regulator-always-on;
						phandle = <0x02>;

						regulator-state-mem {
							regulator-off-in-suspend;
							regulator-suspend-microvolt = <0x9eb10>;
						};
					};

					DCDC_REG2 {
						regulator-name = "dcdc2";
						regulator-min-microvolt = <0x7a120>;
						regulator-max-microvolt = <0x34a490>;
						regulator-ramp-delay = <0x1388>;
						regulator-always-on;
					};

					DCDC_REG3 {
						regulator-name = "dcdc3";
						regulator-min-microvolt = <0x7a120>;
						regulator-max-microvolt = <0x1b7740>;
						regulator-ramp-delay = <0x1388>;
						regulator-always-on;
						phandle = <0x52>;
					};

					DCDC_REG4 {
						regulator-name = "dcdc4";
						regulator-min-microvolt = <0x7a120>;
						regulator-max-microvolt = <0x325aa0>;
						regulator-ramp-delay = <0x1388>;
						regulator-always-on;
						phandle = <0x4f>;

						regulator-state-mem {
							regulator-off-in-suspend;
							regulator-suspend-microvolt = <0x325aa0>;
						};
					};

					DCDC_REG5 {
						regulator-name = "dcdc5";
						regulator-min-microvolt = <0x7a120>;
						regulator-max-microvolt = <0x34a490>;
						regulator-ramp-delay = <0x1388>;
						regulator-always-on;
						phandle = <0x3b>;
					};

					DCDC_REG6 {
						regulator-name = "dcdc6";
						regulator-min-microvolt = <0x7a120>;
						regulator-max-microvolt = <0x34a490>;
						regulator-ramp-delay = <0x1388>;
						regulator-always-on;
					};

					LDO_REG1 {
						regulator-name = "ldo1";
						regulator-min-microvolt = <0x7a120>;
						regulator-max-microvolt = <0x33e140>;
						regulator-boot-on;
						phandle = <0x50>;

						regulator-state-mem {
							regulator-off-in-suspend;
							regulator-suspend-microvolt = <0x7a120>;
						};
					};

					LDO_REG2 {
						regulator-name = "ldo2";
						regulator-min-microvolt = <0x7a120>;
						regulator-max-microvolt = <0x33e140>;
						phandle = <0x7a>;

						regulator-state-mem {
							regulator-off-in-suspend;
							regulator-suspend-microvolt = <0x7a120>;
						};
					};

					LDO_REG3 {
						regulator-name = "ldo3";
						regulator-min-microvolt = <0x7a120>;
						regulator-max-microvolt = <0x33e140>;
						phandle = <0x79>;

						regulator-state-mem {
							regulator-off-in-suspend;
							regulator-suspend-microvolt = <0x7a120>;
						};
					};

					LDO_REG4 {
						regulator-name = "ldo4";
						regulator-min-microvolt = <0x7a120>;
						regulator-max-microvolt = <0x33e140>;

						regulator-state-mem {
							regulator-off-in-suspend;
							regulator-suspend-microvolt = <0x7a120>;
						};
					};

					LDO_REG5 {
						regulator-name = "ldo5";
						regulator-min-microvolt = <0x7a120>;
						regulator-max-microvolt = <0x33e140>;
						regulator-boot-on;
						phandle = <0x70>;

						regulator-state-mem {
							regulator-off-in-suspend;
							regulator-suspend-microvolt = <0x7a120>;
						};
					};

					LDO_REG6 {
						regulator-name = "ldo6";
						regulator-min-microvolt = <0x7a120>;
						regulator-max-microvolt = <0x33e140>;
						phandle = <0x7c>;

						regulator-state-mem {
							regulator-off-in-suspend;
							regulator-suspend-microvolt = <0x7a120>;
						};
					};

					LDO_REG7 {
						regulator-name = "ldo7";
						regulator-min-microvolt = <0x7a120>;
						regulator-max-microvolt = <0x33e140>;
						phandle = <0x7b>;

						regulator-state-mem {
							regulator-off-in-suspend;
							regulator-suspend-microvolt = <0x7a120>;
						};
					};

					LDO_REG8 {
						regulator-name = "ldo8";
						regulator-min-microvolt = <0x7a120>;
						regulator-max-microvolt = <0x33e140>;
						regulator-always-on;
					};

					LDO_REG9 {
						regulator-name = "ldo9";
						regulator-min-microvolt = <0x7a120>;
						regulator-max-microvolt = <0x33e140>;
					};

					LDO_REG10 {
						regulator-name = "ldo10";
						regulator-min-microvolt = <0x7a120>;
						regulator-max-microvolt = <0x33e140>;
						regulator-always-on;
					};

					LDO_REG11 {
						regulator-name = "ldo11";
						regulator-min-microvolt = <0x7a120>;
						regulator-max-microvolt = <0x33e140>;
					};

					SWITCH_REG1 {
						regulator-name = "switch1";
					};
				};

				pinctrl {
					compatible = "pmic,pinctrl,spm8821";
					gpio-controller;
					#gpio-cells = <0x02>;
					spacemit,npins = <0x06>;
				};

				key {
					compatible = "pmic,pwrkey,spm8821";
				};

				rtc {
					compatible = "pmic,rtc,spm8821";
				};

				adc {
					compatible = "pmic,adc,spm8821";
				};
			};
		};

		ri2c@c0887000 {
			compatible = "spacemit,k1x-i2c-rcpu";
			spacemit,adapter-id = <0x09>;
			reg = <0x00 0xc0887000 0x00 0x38>;
			#address-cells = <0x01>;
			#size-cells = <0x00>;
			clocks = <0x03 0xba>;
			resets = <0x1d 0x68>;
			rcpu-i2c;
			spacemit,dma-disable;
			spacemit,i2c-master-code = [0e];
			spacemit,i2c-clk-rate = <0x1e84800>;
			spacemit,i2c-lcr = <0x82c469f>;
			spacemit,i2c-wcr = <0x142a>;
			spacemit,apb_clock = <0x3197500>;
			power-domains = <0x20 0x00>;
			cpuidle,pm-runtime,sleep;
			interconnects = <0x22>;
			interconnect-names = "dma-mem";
			status = "okay";
		};

		pwm@d401a000 {
			compatible = "spacemit,k1x-pwm";
			reg = <0x00 0xd401a000 0x00 0x10>;
			#pwm-cells = <0x01>;
			clocks = <0x03 0x44>;
			resets = <0x1d 0x04>;
			k1x,pwm-disable-fd;
			status = "disabled";
		};

		pwm@d401a400 {
			compatible = "spacemit,k1x-pwm";
			reg = <0x00 0xd401a400 0x00 0x10>;
			#pwm-cells = <0x01>;
			clocks = <0x03 0x45>;
			resets = <0x1d 0x05>;
			k1x,pwm-disable-fd;
			status = "disabled";
		};

		pwm@d401a800 {
			compatible = "spacemit,k1x-pwm";
			reg = <0x00 0xd401a800 0x00 0x10>;
			#pwm-cells = <0x01>;
			clocks = <0x03 0x46>;
			resets = <0x1d 0x06>;
			k1x,pwm-disable-fd;
			status = "disabled";
		};

		pwm@d401ac00 {
			compatible = "spacemit,k1x-pwm";
			reg = <0x00 0xd401ac00 0x00 0x10>;
			#pwm-cells = <0x01>;
			clocks = <0x03 0x47>;
			resets = <0x1d 0x07>;
			k1x,pwm-disable-fd;
			status = "disabled";
		};

		pwm@d401b000 {
			compatible = "spacemit,k1x-pwm";
			reg = <0x00 0xd401b000 0x00 0x10>;
			#pwm-cells = <0x01>;
			clocks = <0x03 0x48>;
			resets = <0x1d 0x08>;
			k1x,pwm-disable-fd;
			status = "okay";
			pinctrl-names = "default";
			pinctrl-0 = <0x3c>;
		};

		pwm@d401b400 {
			compatible = "spacemit,k1x-pwm";
			reg = <0x00 0xd401b400 0x00 0x10>;
			#pwm-cells = <0x01>;
			clocks = <0x03 0x49>;
			resets = <0x1d 0x09>;
			k1x,pwm-disable-fd;
			status = "disabled";
		};

		pwm@d401b800 {
			compatible = "spacemit,k1x-pwm";
			reg = <0x00 0xd401b800 0x00 0x10>;
			#pwm-cells = <0x01>;
			clocks = <0x03 0x4a>;
			resets = <0x1d 0x0a>;
			k1x,pwm-disable-fd;
			status = "disabled";
		};

		pwm@d401bc00 {
			compatible = "spacemit,k1x-pwm";
			reg = <0x00 0xd401bc00 0x00 0x10>;
			#pwm-cells = <0x01>;
			clocks = <0x03 0x4b>;
			resets = <0x1d 0x0b>;
			k1x,pwm-disable-fd;
			status = "disabled";
		};

		pwm@d4020000 {
			compatible = "spacemit,k1x-pwm";
			reg = <0x00 0xd4020000 0x00 0x10>;
			#pwm-cells = <0x01>;
			clocks = <0x03 0x4c>;
			resets = <0x1d 0x0c>;
			k1x,pwm-disable-fd;
			status = "disabled";
		};

		pwm@d4020400 {
			compatible = "spacemit,k1x-pwm";
			reg = <0x00 0xd4020400 0x00 0x10>;
			#pwm-cells = <0x01>;
			clocks = <0x03 0x4d>;
			resets = <0x1d 0x0d>;
			k1x,pwm-disable-fd;
			status = "disabled";
		};

		pwm@d4020800 {
			compatible = "spacemit,k1x-pwm";
			reg = <0x00 0xd4020800 0x00 0x10>;
			#pwm-cells = <0x01>;
			clocks = <0x03 0x4e>;
			resets = <0x1d 0x0e>;
			k1x,pwm-disable-fd;
			status = "disabled";
		};

		pwm@d4020c00 {
			compatible = "spacemit,k1x-pwm";
			reg = <0x00 0xd4020c00 0x00 0x10>;
			#pwm-cells = <0x01>;
			clocks = <0x03 0x4f>;
			resets = <0x1d 0x0f>;
			k1x,pwm-disable-fd;
			status = "disabled";
		};

		pwm@d4021000 {
			compatible = "spacemit,k1x-pwm";
			reg = <0x00 0xd4021000 0x00 0x10>;
			#pwm-cells = <0x01>;
			clocks = <0x03 0x50>;
			resets = <0x1d 0x10>;
			k1x,pwm-disable-fd;
			status = "disabled";
		};

		pwm@d4021400 {
			compatible = "spacemit,k1x-pwm";
			reg = <0x00 0xd4021400 0x00 0x10>;
			#pwm-cells = <0x01>;
			clocks = <0x03 0x51>;
			resets = <0x1d 0x11>;
			k1x,pwm-disable-fd;
			status = "disabled";
		};

		pwm@d4021800 {
			compatible = "spacemit,k1x-pwm";
			reg = <0x00 0xd4021800 0x00 0x10>;
			#pwm-cells = <0x01>;
			clocks = <0x03 0x52>;
			resets = <0x1d 0x12>;
			k1x,pwm-disable-fd;
			status = "disabled";
			pinctrl-names = "default";
			pinctrl-0 = <0x3d>;
			phandle = <0x63>;
		};

		pwm@d4021c00 {
			compatible = "spacemit,k1x-pwm";
			reg = <0x00 0xd4021c00 0x00 0x10>;
			#pwm-cells = <0x01>;
			clocks = <0x03 0x53>;
			resets = <0x1d 0x13>;
			k1x,pwm-disable-fd;
			status = "disabled";
		};

		pwm@d4022000 {
			compatible = "spacemit,k1x-pwm";
			reg = <0x00 0xd4022000 0x00 0x10>;
			#pwm-cells = <0x01>;
			clocks = <0x03 0x54>;
			resets = <0x1d 0x14>;
			k1x,pwm-disable-fd;
			status = "disabled";
		};

		pwm@d4022400 {
			compatible = "spacemit,k1x-pwm";
			reg = <0x00 0xd4022400 0x00 0x10>;
			#pwm-cells = <0x01>;
			clocks = <0x03 0x55>;
			resets = <0x1d 0x15>;
			k1x,pwm-disable-fd;
			status = "disabled";
		};

		pwm@d4022800 {
			compatible = "spacemit,k1x-pwm";
			reg = <0x00 0xd4022800 0x00 0x10>;
			#pwm-cells = <0x01>;
			clocks = <0x03 0x56>;
			resets = <0x1d 0x16>;
			k1x,pwm-disable-fd;
			status = "disabled";
		};

		pwm@d4022c00 {
			compatible = "spacemit,k1x-pwm";
			reg = <0x00 0xd4022c00 0x00 0x10>;
			#pwm-cells = <0x01>;
			clocks = <0x03 0x57>;
			resets = <0x1d 0x17>;
			k1x,pwm-disable-fd;
			status = "disabled";
		};

		pwm@c0888100 {
			compatible = "spacemit,k1x-pwm";
			reg = <0x00 0xc0888100 0x00 0x10>;
			#pwm-cells = <0x01>;
			clocks = <0x03 0xca>;
			resets = <0x1d 0x6d>;
			k1x,pwm-disable-fd;
			rcpu-pwm;
			status = "disabled";
		};

		pwm@c0888200 {
			compatible = "spacemit,k1x-pwm";
			reg = <0x00 0xc0888200 0x00 0x10>;
			#pwm-cells = <0x01>;
			clocks = <0x03 0xcb>;
			resets = <0x1d 0x6e>;
			k1x,pwm-disable-fd;
			rcpu-pwm;
			status = "disabled";
		};

		pwm@c0888300 {
			compatible = "spacemit,k1x-pwm";
			reg = <0x00 0xc0888300 0x00 0x10>;
			#pwm-cells = <0x01>;
			clocks = <0x03 0xcc>;
			resets = <0x1d 0x6f>;
			k1x,pwm-disable-fd;
			rcpu-pwm;
			status = "disabled";
		};

		pwm@c0888400 {
			compatible = "spacemit,k1x-pwm";
			reg = <0x00 0xc0888400 0x00 0x10>;
			#pwm-cells = <0x01>;
			clocks = <0x03 0xcd>;
			resets = <0x1d 0x70>;
			k1x,pwm-disable-fd;
			rcpu-pwm;
			status = "disabled";
		};

		pwm@c0888500 {
			compatible = "spacemit,k1x-pwm";
			reg = <0x00 0xc0888500 0x00 0x10>;
			#pwm-cells = <0x01>;
			clocks = <0x03 0xce>;
			resets = <0x1d 0x71>;
			k1x,pwm-disable-fd;
			rcpu-pwm;
			status = "disabled";
		};

		pwm@c0888600 {
			compatible = "spacemit,k1x-pwm";
			reg = <0x00 0xc0888600 0x00 0x10>;
			#pwm-cells = <0x01>;
			clocks = <0x03 0xcf>;
			resets = <0x1d 0x72>;
			k1x,pwm-disable-fd;
			rcpu-pwm;
			status = "disabled";
		};

		pwm@c0888700 {
			compatible = "spacemit,k1x-pwm";
			reg = <0x00 0xc0888700 0x00 0x10>;
			#pwm-cells = <0x01>;
			clocks = <0x03 0xd0>;
			resets = <0x1d 0x73>;
			k1x,pwm-disable-fd;
			rcpu-pwm;
			status = "disabled";
		};

		pwm@c0888800 {
			compatible = "spacemit,k1x-pwm";
			reg = <0x00 0xc0888800 0x00 0x10>;
			#pwm-cells = <0x01>;
			clocks = <0x03 0xd1>;
			resets = <0x1d 0x74>;
			k1x,pwm-disable-fd;
			rcpu-pwm;
			status = "okay";
			pinctrl-names = "default";
			pinctrl-0 = <0x3e>;
		};

		pwm@c0888900 {
			compatible = "spacemit,k1x-pwm";
			reg = <0x00 0xc0888900 0x00 0x10>;
			#pwm-cells = <0x01>;
			clocks = <0x03 0xd2>;
			resets = <0x1d 0x75>;
			k1x,pwm-disable-fd;
			rcpu-pwm;
			status = "disabled";
		};

		pwm@c0888a00 {
			compatible = "spacemit,k1x-pwm";
			reg = <0x00 0xc0888a00 0x00 0x10>;
			#pwm-cells = <0x01>;
			clocks = <0x03 0xd3>;
			resets = <0x1d 0x76>;
			k1x,pwm-disable-fd;
			rcpu-pwm;
			status = "disabled";
		};

		irc-rx@d4017f00 {
			compatible = "spacemit,k1x-irc";
			reg = <0x00 0xd4017f00 0x00 0x100>;
			interrupts = <0x45>;
			interrupt-parent = <0x1e>;
			clocks = <0x03 0x69>;
			resets = <0x1d 0x23>;
			clock-frequency = <0x61a8000>;
			status = "disabled";
		};

		irc-rx@c088e000 {
			compatible = "spacemit,k1x-rirc";
			reg = <0x00 0xc088e000 0x00 0x100>;
			clocks = <0x03 0xbc>;
			resets = <0x1d 0x6a>;
			clock-frequency = <0x1d4c000>;
			rcpu-ir;
			status = "disabled";
		};

		ddraxi_mon@c0058500 {
			compatible = "spacemit,ddraxi-mon";
			reg = <0x00 0xc0058500 0x00 0x80>;
			status = "ok";
		};

		timer@d4014000 {
			compatible = "spacemit,soc-timer";
			reg = <0x00 0xd4014000 0x00 0xc8>;
			spacemit,timer-id = <0x00>;
			spacemit,timer-fastclk-frequency = <0xc35000>;
			spacemit,timer-apb-frequency = <0x3197500>;
			spacemit,timer-frequency = <0xc35000>;
			clocks = <0x03 0x62>;
			resets = <0x1d 0x1c>;
			status = "ok";

			counter0 {
				compatible = "spacemit,timer-match";
				interrupts = <0x17>;
				interrupt-parent = <0x1e>;
				spacemit,timer-broadcast;
				spacemit,timer-counter-id = <0x00>;
				status = "ok";
			};
		};

		timer@d4016000 {
			compatible = "spacemit,soc-timer";
			reg = <0x00 0xd4016000 0x00 0xc8>;
			spacemit,timer-id = <0x01>;
			spacemit,timer-fastclk-frequency = <0xc35000>;
			spacemit,timer-apb-frequency = <0x3197500>;
			spacemit,timer-frequency = <0xc35000>;
			clocks = <0x03 0x63>;
			resets = <0x1d 0x1e>;
			status = "disabled";

			counter0 {
				compatible = "spacemit,timer-match";
				interrupts = <0x1a>;
				interrupt-parent = <0x1e>;
				spacemit,timer-counter-id = <0x00>;
				status = "disabled";
			};
		};

		watchdog@d4080000 {
			compatible = "spacemit,soc-wdt";
			clocks = <0x03 0x6e>;
			resets = <0x1d 0x34>;
			reg = <0x00 0xd4080000 0x00 0xff 0x00 0xd4050000 0x00 0x1024>;
			interrupts = <0x23>;
			interrupt-parent = <0x1e>;
			spa,wdt-disabled;
			status = "disabled";
		};

		handler@d4282f90 {
			compatible = "spacemit,k1x-reboot";
			reg = <0x00 0xd4282f90 0x00 0x04>;
			status = "ok";
		};

		rtc@d4010000 {
			compatible = "mrvl,mmp-rtc";
			reg = <0x00 0xd4010000 0x00 0x100>;
			interrupt-parent = <0x1e>;
			interrupts = <0x15 0x16>;
			interrupt-names = "rtc 1Hz\0rtc alarm";
			clocks = <0x03 0x59>;
			resets = <0x1d 0x1a>;
			status = "disabled";
		};

		fdcan@d4028000 {
			compatible = "spacemit,k1x-flexcan";
			reg = <0x00 0xd4028000 0x00 0x4000>;
			interrupts = <0x10>;
			interrupt-parent = <0x1e>;
			clocks = <0x03 0x6c 0x03 0x6d>;
			clock-names = "per\0ipg";
			resets = <0x1d 0x33>;
			fsl,clk-source = <0x00>;
			status = "disabled";
		};

		fdcan@c0870000 {
			compatible = "spacemit,k1x-r-flexcan";
			reg = <0x00 0xc0870000 0x00 0x4000>;
			interrupt-parent = <0x1e>;
			fsl,clk-source = <0x00>;
			clocks = <0x03 0xb8 0x03 0xb9>;
			clock-names = "per\0ipg";
			resets = <0x1d 0x67>;
			status = "disabled";
		};

		gpio@d4019000 {
			compatible = "spacemit,k1x-gpio";
			reg = <0x00 0xd4019000 0x00 0x800>;
			gpio-controller;
			#gpio-cells = <0x02>;
			interrupts = <0x3a>;
			clocks = <0x03 0x43>;
			interrupt-names = "gpio_mux";
			interrupt-parent = <0x1e>;
			interrupt-controller;
			#interrupt-cells = <0x02>;
			gpio-ranges = <0x3f 0x31 0x32 0x02 0x3f 0x3a 0x3b 0x01 0x3f 0x3f 0x40 0x01 0x3f 0x41 0x42 0x01 0x3f 0x43 0x44 0x01 0x3f 0x46 0x47 0x04 0x3f 0x4a 0x4b 0x01 0x3f 0x4f 0x50 0x01 0x3f 0x50 0x51 0x04 0x3f 0x5a 0x7f 0x03 0x3f 0x60 0x78 0x02 0x3f 0x6e 0x74 0x01 0x3f 0x6f 0x83 0x01 0x3f 0x71 0x85 0x01 0x3f 0x72 0x86 0x03 0x3f 0x76 0x8a 0x01 0x3f 0x7b 0x8f 0x05>;
			phandle = <0x32>;

			gpio0 {
				reg-offset = <0x00>;
			};

			gpio1 {
				reg-offset = <0x04>;
			};

			gpio2 {
				reg-offset = <0x08>;
			};

			gpio3 {
				reg-offset = <0x100>;
			};
		};

		ethercat_master {
			compatible = "igh,k1x-ec-master";
			run-on-cpu = <0x01>;
			debug-level = <0x00>;
			master-count = <0x01>;
			ec-devices = <0x40 0x41>;
			master-indexes = <0x00 0x00>;
			modes = "ec_main\0ec_backup";
			status = "disable";
		};

		ethernet@cac80000 {
			compatible = "spacemit,k1x-emac";
			reg = <0x00 0xcac80000 0x00 0x420>;
			k1x,apmu-base-reg = <0xd4282800>;
			ctrl-reg = <0x3e4>;
			dline-reg = <0x3e8>;
			clocks = <0x03 0xa5 0x03 0xa6>;
			clock-names = "emac-clk\0ptp-clk";
			resets = <0x1d 0x5d>;
			reset-names = "emac-reset";
			interrupts-extended = <0x1e 0x83>;
			mac-address = [00 00 00 00 00 00];
			ptp-support;
			ptp-clk-rate = <0x989680>;
			power-domains = <0x20 0x00>;
			clk,pm-runtime,no-sleep;
			cpuidle,pm-runtime,sleep;
			interconnects = <0x42>;
			interconnect-names = "dma-mem";
			status = "okay";
			pinctrl-names = "default";
			pinctrl-0 = <0x43>;
			emac,reset-gpio = <0x32 0x6e 0x00>;
			emac,reset-active-low;
			emac,reset-delays-us = <0x00 0x2710 0x186a0>;
			tx-threshold = <0x5ee>;
			rx-threshold = <0x0c>;
			tx-ring-num = <0x400>;
			rx-ring-num = <0x400>;
			dma-burst-len = <0x05>;
			ref-clock-from-phy;
			clk-tuning-enable;
			clk-tuning-by-delayline;
			tx-phase = <0x3c>;
			rx-phase = <0x49>;
			nvmem-cells = <0x44>;
			nvmem-cell-names = "mac-address";
			phy-handle = <0x45>;
			phandle = <0x40>;

			mdio-bus {
				#address-cells = <0x01>;
				#size-cells = <0x00>;

				phy@0 {
					compatible = "ethernet-phy-id001c.c916";
					device_type = "ethernet-phy";
					reg = <0x01>;
					phy-mode = "rgmii";
					phandle = <0x45>;

					leds {
						#address-cells = <0x01>;
						#size-cells = <0x00>;

						lan0-led1@1 {
							reg = <0x01>;
							linux,default-trigger = "netdev";
						};

						lan0-led2@2 {
							reg = <0x02>;
							linux,default-trigger = "netdev";
						};
					};
				};
			};
		};

		ethernet@cac81000 {
			compatible = "spacemit,k1x-emac";
			reg = <0x00 0xcac81000 0x00 0x420>;
			k1x,apmu-base-reg = <0xd4282800>;
			ctrl-reg = <0x3ec>;
			dline-reg = <0x3f0>;
			clocks = <0x03 0xa7 0x03 0xa8>;
			clock-names = "emac-clk\0ptp-clk";
			resets = <0x1d 0x5e>;
			reset-names = "emac-reset";
			interrupts-extended = <0x1e 0x85>;
			mac-address = [00 00 00 00 00 00];
			ptp-support;
			ptp-clk-rate = <0x989680>;
			power-domains = <0x20 0x00>;
			clk,pm-runtime,no-sleep;
			cpuidle,pm-runtime,sleep;
			interconnects = <0x42>;
			interconnect-names = "dma-mem";
			status = "disabled";
			phandle = <0x41>;
		};

		extcon@d428287c {
			compatible = "spacemit,vbus-id";
			reg = <0x00 0xd428287c 0x00 0x04 0x00 0xd4282918 0x00 0x04>;
			reg-names = "reg_pmuap\0pin_state";
			interrupts = <0x6a>;
			interrupt-parent = <0x1e>;
			clocks = <0x03 0x8d>;
			status = "disabled";
		};

		usbphy@c0940000 {
			compatible = "spacemit,usb2-phy";
			reg = <0x00 0xc0940000 0x00 0x200>;
			clocks = <0x03 0x8d>;
			status = "okay";
			phandle = <0x46>;
		};

		otg@c0900100 {
			compatible = "spacemit,mv-otg";
			reg = <0x00 0xc0900100 0x00 0x4000 0x00 0xd428287c 0x00 0x04>;
			interrupts = <0x69>;
			interrupt-parent = <0x1e>;
			spacemit,otg-name = "mv-otg";
			spacemit,otg-force-a-bus-req;
			clocks = <0x03 0x8d>;
			resets = <0x1d 0x4a>;
			power-domains = <0x20 0x00>;
			clk,pm-runtime,no-sleep;
			cpuidle,pm-runtime,sleep;
			usb-phy = <0x46>;
			status = "disabled";
			usb-role-switch;
			role-switch-user-control;
			spacemit,reset-on-resume;
			role-switch-default-mode = "peripheral";
			vbus-gpios = <0x32 0x7b 0x00>;
			phandle = <0x48>;
		};

		udc@c0900100 {
			compatible = "spacemit,mv-udc";
			reg = <0x00 0xc0900100 0x00 0x4000>;
			interrupts = <0x69>;
			interrupt-parent = <0x1e>;
			spacemit,udc-name = "mv-udc";
			spacemit,otg-force-a-bus-req;
			resets = <0x1d 0x4a>;
			clocks = <0x03 0x8d>;
			usb-phy = <0x46>;
			interconnects = <0x47>;
			interconnect-names = "dma-mem";
			usb-otg = <0x48>;
			status = "okay";
			spacemit,udc-mode = <0x00>;
		};

		ehci@c0900100 {
			compatible = "spacemit,mv-ehci";
			reg = <0x00 0xc0900100 0x00 0x4000 0x00 0xd428287c 0x00 0x04>;
			interrupts = <0x69 0x6a>;
			interrupt-parent = <0x1e>;
			spacemit,ehci-name = "mv-ehci";
			spacemit,otg-force-a-bus-req;
			resets = <0x1d 0x4a>;
			clocks = <0x03 0x8d>;
			power-domains = <0x20 0x00>;
			clk,pm-runtime,no-sleep;
			cpuidle,pm-runtime,sleep;
			usb-phy = <0x46>;
			usb-otg = <0x48>;
			interconnects = <0x47>;
			interconnect-names = "dma-mem";
			status = "disabled";
			spacemit,reset-on-resume;
			spacemit,udc-mode = <0x01>;
		};

		usbphy1@c09c0000 {
			compatible = "spacemit,usb2-phy";
			reg = <0x00 0xc09c0000 0x00 0x200>;
			clocks = <0x03 0x8c>;
			status = "okay";
			phandle = <0x49>;
		};

		otg1@c0980100 {
			compatible = "spacemit,mv-otg";
			reg = <0x00 0xc0980100 0x00 0x4000 0x00 0xd4282bc4 0x00 0x04>;
			interrupts = <0x76>;
			interrupt-parent = <0x1e>;
			spacemit,otg-name = "mv-otg1";
			spacemit,otg-force-a-bus-req;
			clocks = <0x03 0x8c>;
			resets = <0x1d 0x4b>;
			power-domains = <0x20 0x00>;
			clk,pm-runtime,no-sleep;
			cpuidle,pm-runtime,sleep;
			usb-phy = <0x49>;
			status = "disabled";
			usb-role-switch;
			role-switch-user-control;
			spacemit,reset-on-resume;
			role-switch-default-mode = "host";
			vbus-gpios = <0x32 0x7b 0x00>;
			phandle = <0x4a>;
		};

		udc1@c0980100 {
			compatible = "spacemit,mv-udc";
			reg = <0x00 0xc0980100 0x00 0x4000>;
			interrupts = <0x76>;
			interrupt-parent = <0x1e>;
			spacemit,udc-name = "mv-udc1";
			spacemit,otg-force-a-bus-req;
			resets = <0x1d 0x4b>;
			clocks = <0x03 0x8c>;
			usb-phy = <0x49>;
			usb-otg = <0x4a>;
			interconnects = <0x47>;
			interconnect-names = "dma-mem";
			status = "disabled";
			spacemit,udc-mode = <0x01>;
		};

		ehci1@c0980100 {
			compatible = "spacemit,mv-ehci";
			reg = <0x00 0xc0980100 0x00 0x4000 0x00 0xd4282bc4 0x00 0x04>;
			interrupts = <0x76 0x94>;
			interrupt-parent = <0x1e>;
			spacemit,ehci-name = "mv-ehci1";
			spacemit,otg-force-a-bus-req;
			resets = <0x1d 0x4b>;
			clocks = <0x03 0x8c>;
			power-domains = <0x20 0x00>;
			clk,pm-runtime,no-sleep;
			cpuidle,pm-runtime,sleep;
			usb-phy = <0x49>;
			usb-otg = <0x4a>;
			interconnects = <0x47>;
			interconnect-names = "dma-mem";
			status = "okay";
			spacemit,udc-mode = <0x02>;
			spacemit,reset-on-resume;
		};

		phy@c0b10000 {
			compatible = "spacemit,k1x-combphy";
			reg = <0x00 0xc0b10000 0x00 0x800 0x00 0xd4282910 0x00 0x400>;
			reg-names = "puphy\0phy_sel";
			resets = <0x1d 0x4c>;
			reset-names = "phy_rst";
			#phy-cells = <0x01>;
			status = "okay";
			phandle = <0x4b>;
		};

		usb2phy@0xc0a30000 {
			compatible = "spacemit,usb2-phy";
			reg = <0x00 0xc0a30000 0x00 0x200>;
			spacemit,handle_connect_change;
			clocks = <0x03 0x8e>;
			status = "okay";
			phandle = <0x4c>;
		};

		usb3hub@0 {
			compatible = "spacemit,usb3-hub";
			power-domains = <0x20 0x08>;
			clk,pm-runtime,no-sleep;
			cpuidle,pm-runtime,sleep;
			status = "okay";
			hub-gpios = <0x32 0x7f 0x00 0x32 0x7b 0x00>;
			vbus-gpios = <0x32 0x4f 0x00>;
			vbus_delay_ms = <0xc8>;
		};

		usb3@0 {
			compatible = "spacemit,k1-x-dwc3";
			#address-cells = <0x02>;
			#size-cells = <0x02>;
			reg = <0x00 0xd4282bc8 0x00 0x04>;
			resets = <0x1d 0x4d>;
			reset-names = "ctl_rst";
			clocks = <0x03 0x8e>;
			clock-names = "usbdrd30";
			power-domains = <0x20 0x00>;
			clk,pm-runtime,no-sleep;
			cpuidle,pm-runtime,sleep;
			phys = <0x4b 0x04>;
			phy-names = "usb3-phy";
			usb-phy = <0x4c>;
			interrupt-parent = <0x1e>;
			interrupts = <0x95>;
			ranges;
			interconnects = <0x47>;
			interconnect-names = "dma-mem";
			status = "okay";
			reset-on-resume;

			dwc3@c0a00000 {
				compatible = "snps,dwc3";
				reg = <0x00 0xc0a00000 0x00 0x10000>;
				interrupt-parent = <0x1e>;
				interrupts = <0x7d>;
				dr_mode = "host";
				phy_type = "utmi";
				snps,hsphy_interface = "utmi";
				snps,dis_enblslpm_quirk;
				snps,dis_u2_susphy_quirk;
				snps,dis_u3_susphy_quirk;
				snps,dis-del-phy-power-chg-quirk;
				snps,dis-tx-ipgap-linecheck-quirk;
				snps,parkmode-disable-ss-quirk;
			};
		};

		sdh@d4280000 {
			compatible = "spacemit,k1-x-sdhci";
			reg = <0x00 0xd4280000 0x00 0x200>;
			interrupts = <0x63>;
			interrupt-parent = <0x1e>;
			resets = <0x1d 0x47 0x1d 0x48>;
			reset-names = "sdh_axi\0sdh0";
			clocks = <0x03 0x89 0x03 0x88 0x03 0x64>;
			clock-names = "sdh-io\0sdh-core\0aib-clk";
			interconnects = <0x47>;
			interconnect-names = "dma-mem";
			power-domains = <0x20 0x00>;
			clk,pm-runtime,no-sleep;
			regulator,pm-runtime,no-sleep;
			cpuidle,pm-runtime,sleep;
			status = "okay";
			pinctrl-names = "default\0fast";
			pinctrl-0 = <0x4d>;
			pinctrl-1 = <0x4e>;
			bus-width = <0x04>;
			cd-gpios = <0x32 0x50 0x00>;
			vmmc-supply = <0x4f>;
			vqmmc-supply = <0x50>;
			no-mmc;
			no-sdio;
			spacemit,sdh-host-caps-disable = <0x30000>;
			spacemit,sdh-quirks = <0x19000>;
			spacemit,sdh-quirks2 = <0x18000008>;
			spacemit,aib_mmc1_io_reg = <0xd401e81c>;
			spacemit,apbc_asfar_reg = <0xd4015050>;
			spacemit,apbc_assar_reg = <0xd4015054>;
			spacemit,rx_dline_reg = <0x00>;
			spacemit,tx_dline_reg = <0x00>;
			spacemit,tx_delaycode = <0x9f>;
			spacemit,rx_tuning_limit = <0x32>;
			spacemit,sdh-freq = "\f5\0";
		};

		sdh@d4280800 {
			compatible = "spacemit,k1-x-sdhci";
			reg = <0x00 0xd4280800 0x00 0x200>;
			interrupts = <0x64>;
			interrupt-parent = <0x1e>;
			resets = <0x1d 0x47 0x1d 0x49>;
			reset-names = "sdh_axi\0sdh1";
			clocks = <0x03 0x8a 0x03 0x88>;
			clock-names = "sdh-io\0sdh-core";
			interconnects = <0x47>;
			interconnect-names = "dma-mem";
			power-domains = <0x20 0x00>;
			clk,pm-runtime,no-sleep;
			regulator,pm-runtime,no-sleep;
			cpuidle,pm-runtime,sleep;
			status = "okay";
			pinctrl-names = "default";
			pinctrl-0 = <0x51>;
			bus-width = <0x04>;
			non-removable;
			vqmmc-supply = <0x52>;
			no-mmc;
			no-sd;
			keep-power-in-suspend;
			spacemit,sdh-host-caps-disable = <0x100020>;
			spacemit,sdh-quirks = <0x9000>;
			spacemit,sdh-quirks2 = <0x10000008>;
			spacemit,rx_dline_reg = <0x00>;
			spacemit,tx_delaycode = <0xa8 0x78>;
			spacemit,rx_tuning_limit = <0x32>;
			spacemit,sdh-freq = <0x165a0bc0>;
		};

		sdh@d4281000 {
			compatible = "spacemit,k1-x-sdhci";
			reg = <0x00 0xd4281000 0x00 0x200>;
			interrupts = <0x65>;
			interrupt-parent = <0x1e>;
			resets = <0x1d 0x47 0x1d 0x54>;
			reset-names = "sdh_axi\0sdh2";
			clocks = <0x03 0x8b 0x03 0x88>;
			clock-names = "sdh-io\0sdh-core";
			interconnects = <0x47>;
			interconnect-names = "dma-mem";
			power-domains = <0x20 0x00>;
			clk,pm-runtime,no-sleep;
			regulator,pm-runtime,no-sleep;
			cpuidle,pm-runtime,sleep;
			status = "okay";
			bus-width = <0x08>;
			non-removable;
			mmc-hs400-1_8v;
			mmc-hs400-enhanced-strobe;
			no-sd;
			no-sdio;
			spacemit,sdh-quirks = <0x9000>;
			spacemit,sdh-quirks2 = <0x08>;
			spacemit,sdh-freq = <0x165a0bc0>;
		};

		pcie@ca000000 {
			compatible = "k1x,dwc-pcie";
			reg = <0x00 0xca000000 0x00 0x1000 0x00 0xca300000 0x00 0x1ff24 0x00 0x8f000000 0x00 0x2000 0x00 0xd4282bcc 0x00 0x08 0x00 0xc0b20000 0x00 0x1000 0x00 0xc0b10000 0x00 0x1000 0x00 0xd4282bcc 0x00 0x08 0x00 0xc0b10000 0x00 0x1000>;
			reg-names = "dbi\0atu\0config\0k1x_conf\0phy_ahb\0phy_addr\0conf0_addr\0phy0_addr";
			k1x,pcie-port = <0x00>;
			clocks = <0x03 0xa2>;
			clock-names = "pcie-clk";
			resets = <0x1d 0x5a>;
			reset-names = "pcie-reset";
			power-domains = <0x20 0x00>;
			bus-range = <0x00 0xff>;
			max-link-speed = <0x02>;
			num-lanes = <0x01>;
			num-viewport = <0x08>;
			device_type = "pci";
			#address-cells = <0x03>;
			#size-cells = <0x02>;
			ranges = <0x1000000 0x00 0x8f002000 0x00 0x8f002000 0x00 0x100000 0x2000000 0x00 0x80000000 0x00 0x80000000 0x00 0xf000000>;
			interconnects = <0x53>;
			interconnect-names = "dma-mem";
			interrupts = <0x8d 0x91>;
			interrupt-parent = <0x1e>;
			#interrupt-cells = <0x01>;
			interrupt-map-mask = <0x00 0x00 0x00 0x07>;
			interrupt-map = <0x00 0x00 0x00 0x01 0x54 0x01 0x00 0x00 0x00 0x02 0x54 0x02 0x00 0x00 0x00 0x03 0x54 0x03 0x00 0x00 0x00 0x04 0x54 0x04>;
			linux,pci-domain = <0x00>;
			status = "disabled";

			interrupt-controller@0 {
				interrupt-controller;
				reg = <0x00 0x00 0x00 0x00 0x00>;
				#address-cells = <0x00>;
				#interrupt-cells = <0x01>;
				phandle = <0x54>;
			};
		};

		pcie@ca400000 {
			compatible = "k1x,dwc-pcie";
			reg = <0x00 0xca400000 0x00 0x1000 0x00 0xca700000 0x00 0x1ff24 0x00 0x9f000000 0x00 0x2000 0x00 0xd4282bd4 0x00 0x08 0x00 0xc0c20000 0x00 0x1000 0x00 0xc0c10000 0x00 0x1000 0x00 0xd4282bcc 0x00 0x08 0x00 0xc0b10000 0x00 0x1000>;
			reg-names = "dbi\0atu\0config\0k1x_conf\0phy_ahb\0phy_addr\0conf0_addr\0phy0_addr";
			k1x,pcie-port = <0x01>;
			clocks = <0x03 0xa3>;
			clock-names = "pcie-clk";
			resets = <0x1d 0x5b>;
			reset-names = "pcie-reset";
			power-domains = <0x20 0x00>;
			bus-range = <0x00 0xff>;
			max-link-speed = <0x02>;
			num-lanes = <0x02>;
			num-viewport = <0x08>;
			device_type = "pci";
			#address-cells = <0x03>;
			#size-cells = <0x02>;
			ranges = <0x1000000 0x00 0x9f002000 0x00 0x9f002000 0x00 0x100000 0x2000000 0x00 0x90000000 0x00 0x90000000 0x00 0xf000000>;
			interconnects = <0x55>;
			interconnect-names = "dma-mem";
			interrupts = <0x8e 0x92>;
			interrupt-parent = <0x1e>;
			#interrupt-cells = <0x01>;
			interrupt-map-mask = <0x00 0x00 0x00 0x07>;
			interrupt-map = <0x00 0x00 0x00 0x01 0x56 0x01 0x00 0x00 0x00 0x02 0x56 0x02 0x00 0x00 0x00 0x03 0x56 0x03 0x00 0x00 0x00 0x04 0x56 0x04>;
			linux,pci-domain = <0x01>;
			status = "okay";
			pinctrl-names = "default";
			pinctrl-0 = <0x57>;

			interrupt-controller@0 {
				interrupt-controller;
				reg = <0x00 0x00 0x00 0x00 0x00>;
				#address-cells = <0x00>;
				#interrupt-cells = <0x01>;
				phandle = <0x56>;
			};
		};

		pcie@ca800000 {
			compatible = "k1x,dwc-pcie";
			reg = <0x00 0xca800000 0x00 0x1000 0x00 0xcab00000 0x00 0x1ff24 0x00 0xb7000000 0x00 0x2000 0x00 0xd4282bdc 0x00 0x08 0x00 0xc0d20000 0x00 0x1000 0x00 0xc0d10000 0x00 0x1000 0x00 0xd4282bcc 0x00 0x08 0x00 0xc0b10000 0x00 0x1000>;
			reg-names = "dbi\0atu\0config\0k1x_conf\0phy_ahb\0phy_addr\0conf0_addr\0phy0_addr";
			k1x,pcie-port = <0x02>;
			clocks = <0x03 0xa4>;
			clock-names = "pcie-clk";
			resets = <0x1d 0x5c>;
			reset-names = "pcie-reset";
			power-domains = <0x20 0x00>;
			bus-range = <0x00 0xff>;
			max-link-speed = <0x02>;
			num-lanes = <0x02>;
			num-viewport = <0x08>;
			device_type = "pci";
			#address-cells = <0x03>;
			#size-cells = <0x02>;
			ranges = <0x1000000 0x00 0xb7002000 0x00 0xb7002000 0x00 0x100000 0x2000000 0x00 0xa0000000 0x00 0xa0000000 0x00 0x17000000>;
			interconnects = <0x58>;
			interconnect-names = "dma-mem";
			interrupts = <0x8f 0x93>;
			interrupt-parent = <0x1e>;
			#interrupt-cells = <0x01>;
			interrupt-map-mask = <0x00 0x00 0x00 0x07>;
			interrupt-map = <0x00 0x00 0x00 0x01 0x59 0x01 0x00 0x00 0x00 0x02 0x59 0x02 0x00 0x00 0x00 0x03 0x59 0x03 0x00 0x00 0x00 0x04 0x59 0x04>;
			linux,pci-domain = <0x02>;
			status = "disabled";
			pinctrl-names = "default";
			pinctrl-0 = <0x5a>;

			interrupt-controller@0 {
				interrupt-controller;
				reg = <0x00 0x00 0x00 0x00 0x00>;
				#address-cells = <0x00>;
				#interrupt-cells = <0x01>;
				phandle = <0x59>;
			};
		};

		spi@d420c000 {
			compatible = "spacemit,k1x-qspi";
			#address-cells = <0x01>;
			#size-cells = <0x00>;
			reg = <0x00 0xd420c000 0x00 0x1000 0x00 0xb8000000 0x00 0xc00000>;
			reg-names = "qspi-base\0qspi-mmap";
			k1x,qspi-sfa1ad = <0x4000000>;
			k1x,qspi-sfa2ad = <0x100000>;
			k1x,qspi-sfb1ad = <0x100000>;
			k1x,qspi-sfb2ad = <0x100000>;
			clocks = <0x03 0x8f 0x03 0x90>;
			clock-names = "qspi_clk\0qspi_bus_clk";
			resets = <0x1d 0x4e 0x1d 0x4f>;
			reset-names = "qspi_reset\0qspi_bus_reset";
			k1x,qspi-pmuap-reg = <0xd4282860>;
			k1x,qspi-mpmu-acgr-reg = <0xd4051024>;
			k1x,qspi-freq = <0x1945ba0>;
			k1x,qspi-id = <0x04>;
			power-domains = <0x20 0x00>;
			cpuidle,pm-runtime,sleep;
			interrupts = <0x75>;
			interrupt-parent = <0x1e>;
			k1x,qspi-tx-dma = <0x01>;
			k1x,qspi-rx-dma = <0x01>;
			dmas = <0x21 0x2d 0x01>;
			dma-names = "tx-dma";
			interconnects = <0x22>;
			interconnect-names = "dma-mem";
			status = "okay";
			pinctrl-names = "default";
			pinctrl-0 = <0x5b>;

			flash@0 {
				compatible = "jedec,spi-nor";
				reg = <0x00>;
				spi-max-frequency = <0x1945ba0>;
				m25p,fast-read;
				broken-flash-reset;
				status = "okay";
			};
		};

		thermal@d4018000 {
			compatible = "spacemit,k1x-tsensor";
			reg = <0x00 0xd4018000 0x00 0x100>;
			interrupt-parent = <0x1e>;
			interrupts = <0x3d>;
			clocks = <0x03 0x6a>;
			clock-names = "thermal_core";
			resets = <0x1d 0x25>;
			reset-names = "tsen_reset";
			sensor_range = <0x03 0x04>;
			#thermal-sensor-cells = <0x01>;
			status = "okay";
			phandle = <0x5c>;
		};

		thermal-zones {

			cluster0_thermal {
				polling-delay = <0x00>;
				polling-delay-passive = <0x00>;
				thermal-sensors = <0x5c 0x03>;

				trips {

					cls0-trip-point0 {
						temperature = <0x124f8>;
						hysteresis = <0x1388>;
						type = "passive";
						phandle = <0x5d>;
					};

					cls0-trip-point1 {
						temperature = <0x14c08>;
						hysteresis = <0x1388>;
						type = "passive";
						phandle = <0x5e>;
					};

					cls0-trip-point2 {
						temperature = <0x17318>;
						hysteresis = <0x1388>;
						type = "passive";
						phandle = <0x5f>;
					};

					cls0-trip-point3 {
						temperature = <0x19a28>;
						hysteresis = <0x1388>;
						type = "passive";
						phandle = <0x60>;
					};

					cls0-trip-point4 {
						temperature = <0x1c138>;
						hysteresis = <0x1388>;
						type = "critical";
					};
				};

				cooling-maps {

					map0 {
						trip = <0x5d>;
						cooling-device = <0x08 0x00 0x00 0x09 0x00 0x00 0x0a 0x00 0x00 0x0b 0x00 0x00 0x0c 0x00 0x00 0x0d 0x00 0x00 0x0e 0x00 0x00 0x0f 0x00 0x00>;
					};

					map1 {
						trip = <0x5e>;
						cooling-device = <0x08 0x01 0x01 0x09 0x01 0x01 0x0a 0x01 0x01 0x0b 0x01 0x01 0x0c 0x01 0x01 0x0d 0x01 0x01 0x0e 0x01 0x01 0x0f 0x01 0x01>;
					};

					map2 {
						trip = <0x5f>;
						cooling-device = <0x08 0x02 0x03 0x09 0x02 0x03 0x0a 0x02 0x03 0x0b 0x02 0x03 0x0c 0x02 0x03 0x0d 0x02 0x03 0x0e 0x02 0x03 0x0f 0x02 0x03>;
					};

					map3 {
						trip = <0x60>;
						cooling-device = <0x08 0x04 0x05 0x09 0x04 0x05 0x0a 0x04 0x05 0x0b 0x04 0x05 0x0c 0x04 0x05 0x0d 0x04 0x05 0x0e 0x04 0x05 0x0f 0x04 0x05>;
					};
				};
			};

			cluster1_thermal {
				polling-delay = <0x00>;
				polling-delay-passive = <0x00>;
				thermal-sensors = <0x5c 0x04>;

				trips {

					cls1-trip-point0 {
						temperature = <0x124f8>;
						hysteresis = <0x1388>;
						type = "passive";
					};

					cls1-trip-point1 {
						temperature = <0x14c08>;
						hysteresis = <0x1388>;
						type = "passive";
					};

					cls1-trip-point2 {
						temperature = <0x17318>;
						hysteresis = <0x1388>;
						type = "passive";
					};

					cls1-trip-point3 {
						temperature = <0x19a28>;
						hysteresis = <0x1388>;
						type = "passive";
					};

					cls1-trip-point4 {
						temperature = <0x1c138>;
						hysteresis = <0x1388>;
						type = "critical";
					};
				};
			};
		};

		tcm@0xd8000000 {
			compatible = "spacemit,k1-x-tcm";
			reg = <0x00 0xd8000000 0x00 0x80000>;
			#address-cells = <0x01>;
			#size-cells = <0x01>;
			ranges = <0x00 0x00 0xd8000000 0x80000>;
			no-memory-wc;

			core0_tcm@0 {
				reg = <0x00 0x20000>;
				pool;
			};

			core1_tcm@20000 {
				reg = <0x20000 0x20000>;
				pool;
			};

			core2_tcm@40000 {
				reg = <0x40000 0x20000>;
				pool;
			};

			core3_tcm@60000 {
				reg = <0x60000 0x20000>;
				pool;
			};
		};

		linlon-v5@c0500000 {
			compatible = "arm china,linlon-v5";
			reg = <0x00 0xc0500000 0x00 0x10000>;
			interrupt-parent = <0x1e>;
			interrupts = <0x4a>;
			clocks = <0x03 0x93>;
			clock-names = "vpu_clk";
			power-domains = <0x20 0x01>;
			resets = <0x1d 0x52>;
			interconnects = <0x61>;
			interconnect-names = "dma-mem";
			clk,pm-runtime,no-sleep;
			status = "okay";
		};

		v2d@c0100000 {
			compatible = "spacemit,v2d";
			reg = <0x00 0xc0100000 0x00 0x1000>;
			reg-names = "v2dreg";
			clocks = <0x03 0x7c 0x03 0x85>;
			clock-names = "v2d-io\0v2d-core";
			resets = <0x1d 0x3f>;
			reset-names = "v2d_reset";
			interrupt-parent = <0x1e>;
			interrupts = <0x56>;
			interconnects = <0x62>;
			interconnect-names = "dma-mem";
			status = "ok";
		};

		jpu@c02f8000 {
			compatible = "chip-media, jpu";
			reg = <0x00 0xc02f8000 0x00 0x700>;
			interrupt-parent = <0x1e>;
			interrupts = <0x57>;
			jpu,chip-id = <0x00>;
			clocks = <0x03 0x70 0x03 0x7c 0x03 0x7a>;
			clock-names = "cclk\0aclk\0iclk";
			power-domains = <0x20 0x04>;
			resets = <0x1d 0x35 0x1d 0x44 0x1d 0x3b 0x1d 0x39 0x1d 0x3a>;
			reset-names = "jpg_reset\0lcd_mclk_reset\0isp_ci_reset\0freset\0sreset";
			jpu,cclk-max-frequency = <0x00 0x3b9aca00>;
			jpu,cclk-min-frequency = <0x1860d840>;
			jpu,cclk-default-frequency = <0x2498e580>;
			page-size = <0x04>;
			interconnects = <0x42>;
			interconnect-names = "dma-mem";
			clk,pm-runtime,no-sleep;
			status = "okay";
		};

		lcd_backlight {
			compatible = "pwm-backlight";
			status = "okay";
			pwms = <0x63 0x7d0>;
			brightness-levels = <0x00 0x28 0x28 0x28 0x28 0x28 0x28 0x28 0x28 0x28 0x28 0x28 0x28 0x28 0x28 0x28 0x28 0x28 0x28 0x28 0x28 0x28 0x28 0x28 0x28 0x28 0x28 0x28 0x28 0x28 0x28 0x28 0x28 0x28 0x28 0x28 0x28 0x28 0x28 0x28 0x28 0x29 0x2a 0x2b 0x2c 0x2d 0x2e 0x2f 0x30 0x31 0x32 0x33 0x34 0x35 0x36 0x37 0x38 0x39 0x3a 0x3b 0x3c 0x3d 0x3e 0x3f 0x40 0x41 0x42 0x43 0x44 0x45 0x46 0x47 0x48 0x49 0x4a 0x4b 0x4c 0x4d 0x4e 0x4f 0x50 0x51 0x52 0x53 0x54 0x55 0x56 0x57 0x58 0x59 0x5a 0x5b 0x5c 0x5d 0x5e 0x5f 0x60 0x61 0x62 0x63 0x64 0x65 0x66 0x67 0x68 0x69 0x6a 0x6b 0x6c 0x6d 0x6e 0x6f 0x70 0x71 0x72 0x73 0x74 0x75 0x76 0x77 0x78 0x79 0x7a 0x7b 0x7c 0x7d 0x7e 0x7f 0x80 0x81 0x82 0x83 0x84 0x85 0x86 0x87 0x88 0x89 0x8a 0x8b 0x8c 0x8d 0x8e 0x8f 0x90 0x91 0x92 0x93 0x94 0x95 0x96 0x97 0x98 0x99 0x9a 0x9b 0x9c 0x9d 0x9e 0x9f 0xa0 0xa1 0xa2 0xa3 0xa4 0xa5 0xa6 0xa7 0xa8 0xa9 0xaa 0xab 0xac 0xad 0xae 0xaf 0xb0 0xb1 0xb2 0xb3 0xb4 0xb5 0xb6 0xb7 0xb8 0xb9 0xba 0xbb 0xbc 0xbd 0xbe 0xbf 0xc0 0xc1 0xc2 0xc3 0xc4 0xc5 0xc6 0xc7 0xc8 0xc9 0xca 0xcb 0xcc 0xcd 0xce 0xcf 0xd0 0xd1 0xd2 0xd3 0xd4 0xd5 0xd6 0xd7 0xd8 0xd9 0xda 0xdb 0xdc 0xdd 0xde 0xdf 0xe0 0xe1 0xe2 0xe3 0xe4 0xe5 0xe6 0xe7 0xe8 0xe9 0xea 0xeb 0xec 0xed 0xee 0xef 0xf0 0xf1 0xf2 0xf3 0xf4 0xf5 0xf6 0xf7 0xf8 0xf9 0xfa 0xfb 0xfc 0xfd 0xfe 0xff>;
			default-brightness-level = <0x64>;
		};

		imggpu@cac00000 {
			compatible = "img,rgx";
			interrupt-names = "rgxirq";
			interrupt-parent = <0x1e>;
			interrupts = <0x4b>;
			reg = <0x00 0xcac00000 0x00 0x80000>;
			reg-names = "rgxregs";
			clocks = <0x03 0x94>;
			clock-names = "gpu_clk";
			resets = <0x1d 0x53>;
			power-domains = <0x20 0x02>;
			interconnects = <0x61>;
			interconnect-names = "dma-mem";
			status = "okay";
		};

		spacemit_crypto_engine@d8600000 {
			compatible = "spacemit,crypto_engine";
			spacemit-crypto-engine-0 = <0xd8600000 0x100000>;
			interrupt-parent = <0x1e>;
			interrupts = <0x71>;
			num-engines = <0x01>;
			clocks = <0x03 0x92>;
			resets = <0x1d 0x51>;
			interconnects = <0x42>;
			interconnect-names = "dma-mem";
			status = "okay";
		};

		crng@f0703800 {
			compatible = "spacemit,hw_crng";
			reg = <0x00 0xf0703800 0x00 0x100>;
			clocks = <0x03 0x92>;
			resets = <0x1d 0x51>;
			status = "okay";
		};

		fuse@f0702800 {
			compatible = "simple-mfd";
			#address-cells = <0x01>;
			#size-cells = <0x01>;
			ranges = <0x00 0x00 0xf0702800 0x400>;
			status = "okay";

			efuse_bank@7 {
				compatible = "spacemit,k1-efuse";
				#address-cells = <0x01>;
				#size-cells = <0x01>;
				reg = <0x190 0x20>;
				resets = <0x1d 0x51>;
				reset-names = "aes_reset";
				clocks = <0x03 0x92>;
				clock-names = "aes_core";
				status = "okay";

				bank7@11,3 {
					reg = <0x11 0x03>;
					bits = <0x03 0x10>;
					phandle = <0x64>;
				};

				bank7@1f,6 {
					reg = <0x1f 0x01>;
					bits = <0x06 0x02>;
					phandle = <0x65>;
				};

				bank7@16,6 {
					reg = <0x16 0x02>;
					bits = <0x06 0x09>;
					phandle = <0x66>;
				};

				bank7@15,5 {
					reg = <0x15 0x02>;
					bits = <0x05 0x09>;
					phandle = <0x67>;
				};

				bank7@17,7 {
					reg = <0x17 0x08>;
					bits = <0x07 0x37>;
					phandle = <0x68>;
				};
			};
		};

		keypad@f0617000 {
			compatible = "marvell,pxa27x-keypad";
			reg = <0x00 0xf0617000 0x00 0x1000 0x00 0xd428287c 0x00 0x04>;
			interrupt-parent = <0x1e>;
			interrupts = <0x3f>;
			clocks = <0x03 0xae>;
			clock-names = "kpc-clk";
			resets = <0x1d 0x64>;
			reset-names = "kpc-reset";
			status = "disabled";
		};

		socinfo@0 {
			compatible = "spacemit,socinfo-k1x";
			status = "okay";
			nvmem-cells = <0x64 0x65 0x66 0x67 0x68>;
			nvmem-cell-names = "soc_die_id\0soc_ver_id\0soc_pack_id\0soc_svt_dro\0soc_chip_id";
		};

		ciu@d4282c00 {
			compatible = "spacemit,aquila-ciu\0spacemit,ciu\0syscon";
			reg = <0x00 0xd4282c00 0x00 0x2d0>;
		};

		display-subsystem-hdmi {
			compatible = "spacemit,saturn-hdmi";
			reg = <0x00 0xc0440000 0x00 0x2a000>;
			ports = <0x69>;
			interconnects = <0x61>;
			interconnect-names = "dma-mem";
		};

		port@c0440000 {
			compatible = "spacemit,dpu-online2";
			interrupt-parent = <0x1e>;
			interrupts = <0x8b 0x8a>;
			interrupt-names = "ONLINE_IRQ\0OFFLINE_IRQ";
			interconnects = <0x61>;
			interconnect-names = "dma-mem";
			clocks = <0x03 0x98>;
			clock-names = "hmclk";
			resets = <0x1d 0x59>;
			reset-names = "hdmi_reset";
			power-domains = <0x20 0x07>;
			pipeline-id = <0x02>;
			ip = "spacemit-saturn";
			type = <0x00>;
			clk,pm-runtime,no-sleep;
			status = "okay";
			memory-region = <0x6a>;
			phandle = <0x69>;

			endpoint@0 {
				remote-endpoint = <0x6b>;
				phandle = <0x6e>;
			};

			endpoint@1 {
			};
		};

		spacemit_snd_sspa@C0883900 {
			compatible = "spacemit,spacemit-snd-sspa";
			reg = <0x00 0xc0883900 0x00 0x300 0x00 0xc0882000 0x00 0x50>;
			clocks = <0x03 0xb7 0x03 0x98>;
			resets = <0x1d 0x66>;
			assigned-clocks = <0x03 0xb7>;
			assigned-clock-rates = <0xbb80>;
			power-domains = <0x20 0x08>;
			function-supply = <0x6c>;
			#sound-dai-cells = <0x00>;
			status = "okay";
			phandle = <0x84>;
		};

		hdmi@C0400500 {
			compatible = "spacemit,hdmi";
			reg = <0x00 0xc0400500 0x00 0x200>;
			interrupt-parent = <0x1e>;
			interrupts = <0x88>;
			clocks = <0x03 0x98>;
			clock-names = "hmclk";
			resets = <0x1d 0x59>;
			reset-names = "hdmi_reset";
			power-domains = <0x20 0x07>;
			clk,pm-runtime,no-sleep;
			status = "okay";
			pinctrl-names = "default";
			pinctrl-0 = <0x6d>;
			phandle = <0x6c>;

			port {
				#address-cells = <0x01>;
				#size-cells = <0x00>;

				endpoint@0 {
					reg = <0x00>;
					remote-endpoint = <0x6e>;
					phandle = <0x6b>;
				};
			};
		};

		display-subsystem-dsi {
			compatible = "spacemit,saturn-le";
			reg = <0x00 0xc0340000 0x00 0x2a000>;
			ports = <0x6f>;
			interconnects = <0x61>;
			interconnect-names = "dma-mem";
		};

		port@c0340000 {
			compatible = "spacemit,dpu-online2";
			interrupt-parent = <0x1e>;
			interrupts = <0x5a 0x59>;
			interrupt-names = "ONLINE_IRQ\0OFFLINE_IRQ";
			clocks = <0x03 0x7f 0x03 0x7c 0x03 0x80 0x03 0x7d 0x03 0x7e>;
			clock-names = "pxclk\0mclk\0hclk\0escclk\0bitclk";
			resets = <0x1d 0x40 0x1d 0x44 0x1d 0x3d 0x1d 0x3e>;
			reset-names = "dsi_reset\0mclk_reset\0lcd_reset\0esc_reset";
			power-domains = <0x20 0x03>;
			pipeline-id = <0x02>;
			ip = "spacemit-saturn";
			spacemit-dpu-min-mclk = <0x2710000>;
			type = <0x01>;
			clk,pm-runtime,no-sleep;
			status = "okay";
			memory-region = <0x6a>;
			spacemit-dpu-bitclk = <0x29b92700>;
			spacemit-dpu-escclk = <0x493e000>;
			dsi_1v2-supply = <0x70>;
			vin-supply-names = "dsi_1v2";
			phandle = <0x6f>;

			endpoint@0 {
				remote-endpoint = <0x71>;
				phandle = <0x75>;
			};

			endpoint@1 {
				remote-endpoint = <0x72>;
				phandle = <0x77>;
			};
		};

		dsi2@d421a800 {
			compatible = "spacemit,dsi2-host";
			#address-cells = <0x01>;
			#size-cells = <0x00>;
			reg = <0x00 0xd421a800 0x00 0x200>;
			interrupt-parent = <0x1e>;
			interrupts = <0x5f>;
			ip = "synopsys-dhost";
			dev-id = <0x02>;
			status = "okay";
			force-attached = "lcd_tc358762xbg_dpi_800x480";

			ports {
				#address-cells = <0x01>;
				#size-cells = <0x00>;

				port@0 {
					reg = <0x00>;
					#address-cells = <0x01>;
					#size-cells = <0x00>;

					endpoint@0 {
						reg = <0x00>;
						remote-endpoint = <0x73>;
						phandle = <0x76>;
					};

					endpoint@1 {
						reg = <0x01>;
						remote-endpoint = <0x74>;
						phandle = <0x36>;
					};
				};

				port@1 {
					reg = <0x01>;

					endpoint {
						remote-endpoint = <0x75>;
						phandle = <0x71>;
					};
				};
			};

			panel@0 {
				status = "ok";
				compatible = "raspberrypi,dpi-panel";
			};
		};

		dphy2@d421a800 {
			compatible = "spacemit,dsi2-phy";
			#address-cells = <0x01>;
			#size-cells = <0x00>;
			reg = <0x00 0xd421a800 0x00 0x200>;
			ip = "spacemit-dphy";
			dev-id = <0x02>;
			status = "okay";

			port@1 {
				reg = <0x01>;

				endpoint {
					remote-endpoint = <0x76>;
					phandle = <0x73>;
				};
			};
		};

		wb0 {
			compatible = "spacemit,wb0";
			dev-id = <0x02>;
			status = "okay";

			ports {
				#address-cells = <0x01>;
				#size-cells = <0x00>;

				port@0 {
					reg = <0x00>;

					endpoint {
						remote-endpoint = <0x77>;
						phandle = <0x72>;
					};
				};
			};
		};

		cam_sensor@0 {
			cell-index = <0x00>;
			twsi-index = <0x00>;
			dphy-index = <0x00>;
			compatible = "spacemit,cam-sensor";
			clocks = <0x03 0x76>;
			clock-names = "cam_mclk0";
			pinctrl-names = "default";
			pinctrl-0 = <0x78>;
			interconnects = <0x61>;
			interconnect-names = "dma-mem";
			status = "okay";
			pwdn-gpios = <0x32 0x71 0x00>;
			dvdd-powen-gpios = <0x32 0x73 0x00>;
			mclk-disable;
		};

		cam_sensor@1 {
			cell-index = <0x01>;
			twsi-index = <0x00>;
			dphy-index = <0x02>;
			compatible = "spacemit,cam-sensor";
			clocks = <0x03 0x76>;
			clock-names = "cam_mclk0";
			pinctrl-names = "mclk_multi";
			pinctrl-0 = <0x78>;
			interconnects = <0x61>;
			interconnect-names = "dma-mem";
			status = "disabled";
			af_2v8-supply = <0x79>;
			avdd_2v8-supply = <0x7a>;
			dovdd_1v8-supply = <0x7b>;
			dvdd_1v2-supply = <0x7c>;
			pwdn-gpios = <0x32 0x7c 0x00>;
			reset-gpios = <0x32 0x61 0x00>;
			pinmulti-enable;
		};

		cam_sensor@2 {
			cell-index = <0x02>;
			twsi-index = <0x01>;
			dphy-index = <0x02>;
			compatible = "spacemit,cam-sensor";
			clocks = <0x03 0x78>;
			clock-names = "cam_mclk2";
			pinctrl-names = "default";
			pinctrl-0 = <0x7d>;
			interconnects = <0x61>;
			interconnect-names = "dma-mem";
			status = "okay";
			pwdn-gpios = <0x32 0x72 0x00>;
			dvdd-powen-gpios = <0x32 0x73 0x00>;
			mclk-disable;
		};

		plat-cam {
			compatible = "spacemit,plat-cam\0simple-bus";
			#address-cells = <0x02>;
			#size-cells = <0x02>;
			interconnects = <0x62>;
			interconnect-names = "dma-mem";
			status = "okay";
		};

		csiphy@d420a000 {
			compatible = "spacemit,csi-dphy";
			cell-index = <0x00>;
			reg = <0x00 0xd420a000 0x00 0x13f>;
			reg-names = "csiphy-regs";
			clocks = <0x03 0x87>;
			clock-names = "csi_dphy";
			resets = <0x1d 0x46>;
			reset-names = "cphy_reset";
			interconnects = <0x62>;
			interconnect-names = "dma-mem";
			status = "okay";
			phandle = <0x7e>;
		};

		csiphy@d420a800 {
			compatible = "spacemit,csi-dphy";
			cell-index = <0x01>;
			reg = <0x00 0xd420a800 0x00 0x13f>;
			reg-names = "csiphy-regs";
			clocks = <0x03 0x73>;
			clock-names = "csi_dphy";
			resets = <0x1d 0x37>;
			reset-names = "cphy_reset";
			interconnects = <0x62>;
			interconnect-names = "dma-mem";
			status = "disabled";
		};

		csiphy@d4206000 {
			compatible = "spacemit,csi-dphy";
			cell-index = <0x02>;
			reg = <0x00 0xd4206000 0x00 0x13f>;
			reg-names = "csiphy-regs";
			clocks = <0x03 0x74>;
			clock-names = "csi_dphy";
			resets = <0x1d 0x38>;
			reset-names = "cphy_reset";
			interconnects = <0x62>;
			interconnect-names = "dma-mem";
			status = "okay";
			spacemit,bifmode-enable;
			phandle = <0x7f>;
		};

		ccic@d420a000 {
			compatible = "spacemit,k1xccic";
			cell-index = <0x00>;
			spacemit,csiphy = <0x7e>;
			reg = <0x00 0xd420a000 0x00 0x3ff>;
			reg-names = "ccic-regs";
			interrupt-parent = <0x1e>;
			interrupts = <0x51>;
			interrupt-names = "ipe-irq";
			clocks = <0x03 0x75 0x03 0x86 0x03 0x7a 0x03 0x7c>;
			clock-names = "csi_func\0ccic_func\0isp_axi\0dpu_mclk";
			resets = <0x1d 0x3a 0x1d 0x36 0x1d 0x45 0x1d 0x3b 0x1d 0x44>;
			reset-names = "isp_ahb_reset\0csi_reset\0ccic_4x_reset\0isp_ci_reset\0mclk_reset";
			interconnects = <0x62>;
			interconnect-names = "dma-mem";
			status = "okay";
			power-domains = <0x20 0x04>;
		};

		ccic@d420a800 {
			compatible = "spacemit,k1xccic";
			cell-index = <0x01>;
			spacemit,csiphy = <0x7f>;
			reg = <0x00 0xd420a800 0x00 0x3ff>;
			reg-names = "ccic-regs";
			interrupt-parent = <0x1e>;
			interrupts = <0x52>;
			interrupt-names = "ipe-irq";
			clocks = <0x03 0x75 0x03 0x86 0x03 0x7a 0x03 0x7c>;
			clock-names = "csi_func\0ccic_func\0isp_axi\0dpu_mclk";
			resets = <0x1d 0x3a 0x1d 0x36 0x1d 0x45 0x1d 0x3b 0x1d 0x44>;
			reset-names = "isp_ahb_reset\0csi_reset\0ccic_4x_reset\0isp_ci_reset\0mclk_reset";
			interconnects = <0x62>;
			interconnect-names = "dma-mem";
			status = "okay";
			power-domains = <0x20 0x04>;
		};

		ccic@d4206000 {
			compatible = "spacemit,k1xccic";
			cell-index = <0x02>;
			spacemit,csiphy = <0x7f>;
			reg = <0x00 0xd4206000 0x00 0x3ff>;
			reg-names = "ccic-regs";
			interrupt-parent = <0x1e>;
			interrupts = <0x53>;
			interrupt-names = "ipe-irq";
			clocks = <0x03 0x75 0x03 0x86 0x03 0x7a 0x03 0x7c>;
			clock-names = "csi_func\0ccic_func\0isp_axi\0dpu_mclk";
			resets = <0x1d 0x3a 0x1d 0x36 0x1d 0x45 0x1d 0x3b 0x1d 0x44>;
			reset-names = "isp_ahb_reset\0csi_reset\0ccic_4x_reset\0isp_ci_reset\0mclk_reset";
			interconnects = <0x62>;
			interconnect-names = "dma-mem";
			status = "okay";
			power-domains = <0x20 0x04>;
		};

		isp@C0230000 {
			compatible = "spacemit,k1xisp";
			reg = <0x00 0xc0230000 0x00 0x12700>;
			reg-names = "isp";
			interrupt-parent = <0x1e>;
			interrupts = <0x4f 0x55>;
			interrupt-names = "feisp-irq\0feisp-dma-irq";
			clocks = <0x03 0x7b 0x03 0x7a 0x03 0x7c>;
			clock-names = "isp_func\0isp_axi\0dpu_mclk";
			resets = <0x1d 0x3a 0x1d 0x39 0x1d 0x3b 0x1d 0x44>;
			reset-names = "isp_ahb_reset\0isp_reset\0isp_ci_reset\0lcd_mclk_reset";
			interconnects = <0x62>;
			interconnect-names = "dma-mem";
			status = "okay";
			power-domains = <0x20 0x04>;
		};

		vi@C0230000 {
			compatible = "spacemit,k1xvi";
			reg = <0x00 0xc0230000 0x00 0x14000>;
			reg-names = "vi";
			interrupt-parent = <0x1e>;
			interrupts = <0x4f 0x55>;
			interrupt-names = "feisp-irq\0feisp-dma-irq";
			clocks = <0x03 0x7b 0x03 0x7a 0x03 0x7c>;
			clock-names = "isp_func\0isp_axi\0dpu_mclk";
			resets = <0x1d 0x3a 0x1d 0x39 0x1d 0x3b 0x1d 0x44>;
			reset-names = "isp_ahb_reset\0isp_reset\0isp_ci_reset\0lcd_mclk_reset";
			interconnects = <0x62>;
			interconnect-names = "dma-mem";
			status = "okay";
			power-domains = <0x20 0x04>;
		};

		cpp@C02f0000 {
			compatible = "spacemit,k1xcpp";
			reg = <0x00 0xc02f0000 0x00 0x7fff>;
			reg-names = "cpp";
			interrupt-parent = <0x1e>;
			interrupts = <0x54>;
			interrupt-names = "cpp";
			clocks = <0x03 0x79 0x03 0x7a 0x03 0x7c>;
			clock-names = "cpp_func\0isp_axi\0dpu_mclk";
			resets = <0x1d 0x3a 0x1d 0x3c 0x1d 0x3b 0x1d 0x44>;
			reset-names = "isp_ahb_reset\0isp_cpp_reset\0isp_ci_reset\0lcd_mclk_reset";
			interconnects = <0x62>;
			interconnect-names = "dma-mem";
			status = "okay";
			power-domains = <0x20 0x04>;
		};
	};

	pmu {
		compatible = "riscv,pmu";
		riscv,event-to-mhpmevent = <0x05 0x00 0x01 0x06 0x00 0x02 0x08 0x00 0x03 0x09 0x00 0x04 0x10000 0x00 0x06 0x10001 0x00 0x05 0x10002 0x00 0x0a 0x10003 0x00 0x09 0x10008 0x00 0x0c 0x10009 0x00 0x0b 0x1000c 0x00 0x0e 0x1000d 0x00 0x0d 0x10019 0x00 0x15 0x1001b 0x00 0x19 0x10021 0x00 0x1b>;
		riscv,event-to-mhpmcounters = <0x05 0x06 0x7fff8 0x08 0x09 0x7fff8 0x10000 0x10003 0x7fff8 0x10008 0x10009 0x7fff8 0x1000c 0x1000d 0x7fff8 0x10019 0x10019 0x7fff8 0x1001b 0x1001b 0x7fff8 0x10021 0x10021 0x7fff8>;
		riscv,raw-event-to-mhpmcounters = <0x00 0x00 0xffffffff 0xffffff00 0x7fff8>;
	};

	spacemit_snd_dma_hdmi {
		compatible = "spacemit,spacemit-snd-dma-hdmi";
		reg = <0x00 0xc08d0400 0x00 0x3c00>;
		dmas = <0x80>;
		dma-names = "tx";
		#sound-dai-cells = <0x00>;
		status = "okay";
		phandle = <0x82>;
	};

	dummy_codec {
		compatible = "spacemit,dummy-codec";
		#sound-dai-cells = <0x00>;
		status = "okay";
		phandle = <0x83>;
	};

	i2s0@d4026000 {
		compatible = "spacemit,spacemit-i2s0";
		reg = <0x00 0xd4026000 0x00 0x30>;
		reg-names = "i2s0";
		#sound-dai-cells = <0x00>;
		clocks = <0x03 0xdb 0x03 0x66>;
		clock-names = "sspa-i2S-clk\0sspa-clk";
		resets = <0x1d 0x20>;
		reset-names = "sspa-rst";
		assigned-clocks = <0x03 0xdb 0x03 0x66>;
		assigned-clock-rates = <0x177000 0x177000>;
		power-domains = <0x20 0x08>;
		status = "okay";
		pinctrl-names = "default";
		pinctrl-0 = <0x81>;
		phandle = <0x85>;
	};

	i2s1@d4026800 {
		compatible = "spacemit,spacemit-i2s1";
		reg = <0x00 0xd4026800 0x00 0x30>;
		reg-names = "i2s1";
		#sound-dai-cells = <0x00>;
		clocks = <0x03 0xdb 0x03 0x67>;
		clock-names = "sspa-i2S-clk\0sspa-clk";
		resets = <0x1d 0x21>;
		reset-names = "sspa-rst";
		assigned-clocks = <0x03 0xdb 0x03 0x67>;
		assigned-clock-rates = <0x177000 0x177000>;
		power-domains = <0x20 0x08>;
		status = "disabled";
	};

	i2s3@d401c000 {
		compatible = "spacemit,spacemit-i2s3";
		reg = <0x00 0xd401c000 0x00 0x30>;
		reg-names = "i2s3";
		#sound-dai-cells = <0x00>;
		clocks = <0x03 0xda 0x03 0x58>;
		clock-names = "sspa-i2S-clk\0sspa-clk";
		resets = <0x1d 0x18>;
		reset-names = "sspa-rst";
		assigned-clocks = <0x03 0xda 0x03 0x58>;
		assigned-clock-rates = <0x177000 0x177000>;
		power-domains = <0x20 0x00>;
		status = "disabled";
	};

	spacemit-snd-dma0 {
		compatible = "spacemit,spacemit-snd-dma0";
		dmas = <0x21 0x16 0x01 0x21 0x15 0x01>;
		dma-names = "rx\0tx";
		#sound-dai-cells = <0x00>;
		status = "okay";
		phandle = <0x86>;
	};

	spacemit-snd-dma1 {
		compatible = "spacemit,spacemit-snd-dma1";
		dmas = <0x21 0x18 0x01 0x21 0x17 0x01>;
		dma-names = "rx\0tx";
		#sound-dai-cells = <0x00>;
		status = "okay";
	};

	spacemit-snd-dma3 {
		compatible = "spacemit,spacemit-snd-dma3";
		dmas = <0x21 0x14 0x01 0x21 0x13 0x01>;
		dma-names = "rx\0tx";
		#sound-dai-cells = <0x00>;
		status = "okay";
	};

	snd-card@0 {
		compatible = "spacemit,simple-audio-card";
		simple-audio-card,name = "snd-hdmi";
		simple-audio-card,playback_only;
		status = "okay";
		interconnects = <0x22>;
		interconnect-names = "dma-mem";

		simple-audio-card,plat {
			sound-dai = <0x82>;
		};

		simple-audio-card,codec {
			sound-dai = <0x83>;
		};

		simple-audio-card,cpu {
			sound-dai = <0x84>;
		};
	};

	snd-card@1 {
		compatible = "spacemit,simple-audio-card";
		simple-audio-card,format = "i2s";
		status = "okay";
		interconnects = <0x22>;
		interconnect-names = "dma-mem";
		spacemit,init-jack;
		simple-audio-card,name = "snd-es8326";
		spacemit,mclk-fs = <0x40>;

		simple-audio-card,cpu {
			sound-dai = <0x85>;
		};

		simple-audio-card,plat {
			sound-dai = <0x86>;
		};

		simple-audio-card,codec {
			sound-dai = <0x87>;
		};
	};

	lcds {
		status = "okay";

		lcd_tc358762xbg_dpi_800x480 {
			dsi-work-mode = <0x01>;
			dsi-lane-number = <0x01>;
			dsi-color-format = "rgb888";
			width-mm = <0x5f>;
			height-mm = <0x35>;
			use-dcs-write;
			height = <0x1e0>;
			width = <0x320>;
			hfp = <0x01>;
			hbp = <0x2e>;
			hsync = <0x02>;
			vfp = <0x07>;
			vbp = <0x15>;
			vsync = <0x02>;
			fps = <0x37>;
			work-mode = <0x00>;
			rgb-mode = <0x03>;
			lane-number = <0x01>;
			phy-bit-clock = <0x29b92700>;
			split-enable = <0x00>;
			eotp-enable = <0x00>;
			burst-mode = <0x02>;
			esd-check-enable = <0x00>;
			initial-command = [39 01 f0 01 11 39 01 28 01 29];
			sleep-in-command = [39 01 78 01 28 39 01 78 01 10];
			sleep-out-command = [39 01 96 01 11 39 01 32 01 29];

			display-timings {

				timing0 {
					clock-frequency = <0x17d7840>;
					hactive = <0x320>;
					hfront-porch = <0x01>;
					hback-porch = <0x2e>;
					hsync-len = <0x02>;
					vactive = <0x1e0>;
					vfront-porch = <0x07>;
					vback-porch = <0x15>;
					vsync-len = <0x02>;
					vsync-active = <0x01>;
					hsync-active = <0x01>;
				};
			};
		};
	};

	memory@0 {
		device_type = "memory";
		reg = <0x00 0x00 0x00 0x80000000>;
	};

	memory@100000000 {
		device_type = "memory";
		reg = <0x01 0x00 0x00 0x80000000>;
	};

	chosen {
		bootargs = "console=ttyS0,115200n8 loglevel=1 swiotlb=65536 rdinit=/init driver_async_probe=spacemit-hdmi-drv,i2c-spacemit-k1x,ri2c-spacemit-k1x,k1xccic,sdhci-spacemit,k1x-dwc-pcie,pxa2xx-uart";
		stdout-path = "serial0:115200n8";
	};

	dc-12v {
		compatible = "regulator-fixed";
		regulator-name = "dc_12v";
		regulator-always-on;
		regulator-boot-on;
		regulator-min-microvolt = <0xb71b00>;
		regulator-max-microvolt = <0xb71b00>;
		phandle = <0x88>;
	};

	vcc4v0-baseboard {
		compatible = "regulator-fixed";
		regulator-name = "vcc4v0_baseboard";
		regulator-always-on;
		regulator-boot-on;
		regulator-min-microvolt = "\0=\t";
		regulator-max-microvolt = "\0=\t";
		vin-supply = <0x88>;
		phandle = <0x3a>;
	};

	rf-pwrseq {
		compatible = "spacemit,rf-pwrseq";
		io-supply = <0x52>;
		io_voltage = <0x1b7740>;
		pwr-gpios = <0x32 0x43 0x00>;
		status = "okay";

		wlan-pwrseq {
			compatible = "spacemit,wlan-pwrseq";
			regon-gpios = <0x32 0x74 0x00>;
			interrupt-parent = <0x3f>;
			interrupts = <0x10c>;
			pinctrl-names = "default";
			pinctrl-0 = <0x89>;
		};

		bt-pwrseq {
			compatible = "spacemit,bt-pwrseq";
			reset-gpios = <0x32 0x3f 0x00>;
		};
	};

	leds {
		compatible = "gpio-leds";

		led1 {
			label = "sys-led";
			gpios = <0x32 0x60 0x00>;
			linux,default-trigger = "none";
			default-state = "on";
			status = "okay";
		};
	};
};
